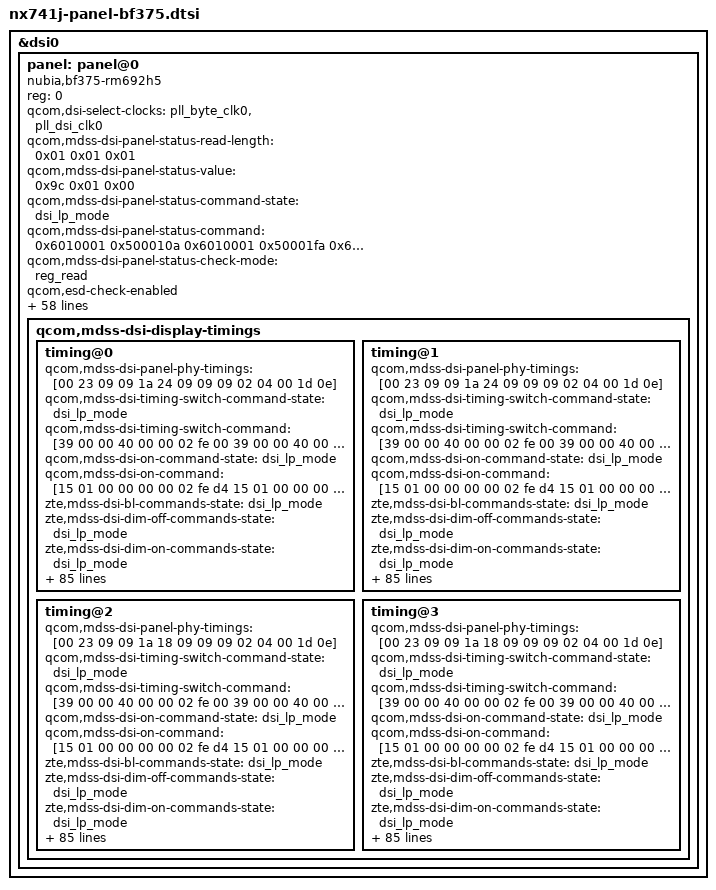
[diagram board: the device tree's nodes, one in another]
/*
 * Nubia Z80 Ultra (NX741J) display panel: BOE BF375 + Raydium RM692H5.
 *
 * Extracted from the live Android FDT (adb pull /sys/firmware/fdt) and reduced
 * to the properties the panel driver needs. Backlight is DCS command based
 * (qcom,mdss-dsi-bl-pmic-control-type = "bl_ctrl_dcs"), so it is driven with
 * the panel's own 0x51/0x53 commands rather than a PMIC PWM channel.
 *
 * Attached to the &dsi0 controller from nx741j-mdss.dtsi.  qcom,dsi-display-primary
 * in that file points qcom,dsi-default-panel at this node through the "panel"
 * label, and qcom,panel-supply-entries uses the dsi_panel_pwr_supply node.
 */

&dsi0 {
	panel: panel@0 {
		compatible = "nubia,bf375-rm692h5";
		reg = <0>;
				qcom,dsi-select-clocks = "pll_byte_clk0", "pll_dsi_clk0";
				qcom,mdss-dsi-panel-status-read-length = <0x01 0x01 0x01>;
				qcom,mdss-dsi-panel-status-value = <0x9c 0x01 0x00>;
				qcom,mdss-dsi-panel-status-command-state = "dsi_lp_mode";
				qcom,mdss-dsi-panel-status-command = <0x6010001 0x500010a 0x6010001 0x50001fa 0x6010001 0x500010b>;
				qcom,mdss-dsi-panel-status-check-mode = "reg_read";
				qcom,esd-check-enabled;
				qcom,ulps-enabled;
				qcom,platform-reset-gpio = <&tlmm 0x62 0x00>;
				qcom,mdss-dsi-bl-inverted-dbv;
				qcom,mdss-brightness-max-level = <0x1ffe>;
				qcom,mdss-dsi-bl-pmic-control-type = "bl_ctrl_dcs";
				qcom,panel-supply-entries = <&dsi_panel_pwr_supply>;
				zte,bl-normalmax-level = <0x1b76>;
				zte,te-high-width = <0x2134>;
				zte,bl_limit_enabled;
				zte,color_space_enabled;
				zte,acl_enabled;
				zte,aod_enabled;
				zte,fps_enabled;
				zte,hbm_enabled;
				qcom,mdss-disable-cesta-hw-sleep;
				qcom,bl-dsc-cmd-state = "dsi_lp_mode";
				qcom,bl-dcs-cmd-state = "dsi_lp_mode";
				qcom,mdss-pan-physical-height-dimension = <0x9e>;
				qcom,mdss-pan-physical-width-dimension = <0x48>;
				qcom,mdss-dsi-panel-blackness-level = <0x14>;
				qcom,mdss-dsi-panel-peak-brightness = <0x65edc0>;
				qcom,mdss-dsi-panel-hdr-color-primaries = <0x38a4 0x3c8c 0x84df 0x3e6c 0x32e6 0x876e 0x1b26 0xa05>;
				qcom,mdss-dsi-panel-hdr-enabled;
				qcom,mdss-dsi-bl-max-level = <0x1ffe>;
				qcom,mdss-dsi-bl-min-level = <0x02>;
				qcom,mdss-dsi-te-using-te-pin;
				qcom,mdss-dsi-te-check-enable;
				qcom,mdss-dsi-te-dcs-command = <0x01>;
				qcom,mdss-dsi-te-pin-select = <0x01>;
				qcom,mdss-dsi-reset-sequence = <0x01 0x0a 0x00 0x0a 0x01 0x28>;
				qcom,mdss-dsi-mdp-trigger = "none";
				qcom,mdss-dsi-dma-trigger = "trigger_sw";
				qcom,mdss-dsi-tx-eot-append;
				qcom,mdss-dsi-lp11-init;
				qcom,mdss-dsi-lane-3-state;
				qcom,mdss-dsi-lane-2-state;
				qcom,mdss-dsi-lane-1-state;
				qcom,mdss-dsi-lane-0-state;
				qcom,mdss-dsi-bllp-power-mode;
				qcom,mdss-dsi-bllp-eof-power-mode;
				qcom,mdss-dsi-lane-map = "lane_map_0123";
				qcom,mdss-dsi-traffic-mode = "burst_mode";
				qcom,dsi-phy-num = <0x00>;
				qcom,dsi-ctrl-num = <0x00>;
				qcom,mdss-dsi-border-color = <0x00>;
				qcom,mdss-dsi-underflow-color = <0xff>;
				qcom,mdss-dsi-color-order = "rgb_swap_rgb";
				qcom,mdss-dsi-bpp = <0x18>;
				qcom,mdss-dsi-stream = <0x00>;
				qcom,mdss-dsi-virtual-channel-id = <0x00>;
				qcom,mdss-dsi-panel-physical-type = "oled";
				qcom,mdss-dsi-panel-type = "dsi_cmd_mode";
				qcom,mdss-dsi-panel-name = "BF375_RM692H5_6P8_DEV0_DSC_CMD";

				qcom,mdss-dsi-display-timings {

					timing@0 {
						qcom,mdss-dsi-panel-phy-timings = [00 23 09 09 1a 24 09 09 09 02 04 00 1d 0e];
						qcom,mdss-dsi-timing-switch-command-state = "dsi_lp_mode";
						qcom,mdss-dsi-timing-switch-command = [39 00 00 40 00 00 02 fe 00 39 00 00 40 00 00 02 2f 07 39 00 00 40 00 00 02 fe 5a 39 00 00 40 00 00 02 47 f0 39 00 00 40 00 00 02 48 df 39 00 00 40 00 00 02 49 20 39 00 00 40 00 00 02 4a ee 39 00 00 40 00 00 02 4b ee 39 00 00 40 00 00 02 4c ee 39 00 00 40 00 00 02 4f 10 39 00 00 40 00 00 02 50 16 39 00 00 40 00 00 02 51 00 39 00 00 40 00 00 02 53 08 39 00 00 40 00 00 02 58 00 39 00 00 40 00 00 02 59 00 39 00 00 40 00 00 02 60 00 39 00 00 40 00 00 02 61 00 39 00 00 40 00 00 02 68 f6 39 00 00 40 00 00 02 69 00 39 00 00 40 00 00 02 70 00 39 00 00 40 00 00 02 79 00 39 00 00 40 00 00 02 7a ff 39 00 00 40 00 00 02 7f 01 39 00 00 40 00 00 02 80 00 39 00 00 40 00 00 02 88 ff 39 00 00 40 00 00 02 89 ff 39 00 00 40 00 00 02 8a ff 39 00 00 40 00 00 02 8c 00 39 00 00 40 00 00 02 90 20 39 00 00 40 00 00 02 91 30 39 00 00 40 00 00 02 92 00 39 00 00 40 00 00 02 93 10 39 00 00 40 00 00 02 94 09 39 00 00 40 00 00 02 95 10 39 00 00 40 00 00 02 98 0c 39 00 00 40 00 00 02 99 01 39 00 00 40 00 00 02 9a 02 39 00 00 40 00 00 02 a0 02 39 00 00 40 00 00 02 a2 06 39 00 00 40 00 00 02 a3 04 39 00 00 40 00 00 02 aa 00 39 00 00 40 00 00 02 ab 02 39 00 00 40 00 00 02 b2 06 39 00 00 40 00 00 02 b3 02 39 00 00 40 00 00 02 ba 01 39 00 00 40 00 00 02 bb 03 39 00 00 40 00 00 02 bc 02 39 00 00 40 00 00 02 bd 03 39 00 00 40 00 00 02 c2 03 39 00 00 40 00 00 02 c3 03 39 00 00 40 00 00 02 c4 02 39 00 00 40 00 00 02 c9 02 39 00 00 40 00 00 02 ca 01 39 00 00 40 00 00 02 cb 01 39 00 00 40 00 00 02 da 40 39 00 00 40 00 00 02 db 30 39 00 00 40 00 00 02 dc 2a 39 00 00 40 00 00 02 dd 06 39 00 00 40 00 00 02 de 10 39 00 00 40 00 00 02 df 06 39 00 00 40 00 00 02 e2 1f 39 00 00 40 00 00 02 e3 20 39 00 00 40 00 00 02 e4 0d 39 00 00 40 00 00 02 ea 12 39 00 00 40 00 00 02 eb 10 39 00 00 40 00 00 02 ec 10 39 00 00 40 00 00 02 f3 04 39 00 00 40 00 00 02 f4 06 39 00 00 40 00 00 02 fe 5b 39 00 00 40 00 00 02 01 10 39 00 00 40 00 00 02 02 06 39 00 00 40 00 00 02 03 02 39 00 00 40 00 00 02 09 03 39 00 00 40 00 00 02 0a 02 39 00 00 40 00 00 02 11 02 39 00 00 40 00 00 02 12 02 39 00 00 40 00 00 02 18 02 39 00 00 40 00 00 02 19 02 39 00 00 40 00 00 02 1b ff 39 00 00 40 00 00 02 21 02 39 00 00 40 00 00 02 22 01 39 00 00 40 00 00 02 23 01 39 00 00 40 00 00 02 24 01 39 00 00 40 00 00 02 25 02 39 00 00 40 00 00 02 29 7f 39 00 00 40 00 00 02 2b fd 39 00 00 40 00 00 02 2d 1f 39 00 00 40 00 00 02 2f 1b 39 00 00 40 00 00 02 30 36 39 00 00 40 00 00 02 33 f9 39 00 00 40 00 00 02 34 00 39 00 00 40 00 00 02 35 fc 39 00 00 40 00 00 02 3b fd 39 00 00 40 00 00 02 3d ff 39 00 00 40 00 00 02 45 fb 39 00 00 40 00 00 02 46 00 39 00 00 40 00 00 02 55 00 39 00 00 40 00 00 02 56 fd 39 00 00 40 00 00 02 5e ff 39 00 00 40 00 00 02 5f 01 39 00 00 40 00 00 02 60 02 39 00 00 40 00 00 02 65 fe 39 00 00 40 00 00 02 66 ff 39 00 00 40 00 00 02 67 01 39 00 00 40 00 00 02 6e 01 39 00 00 40 00 00 02 6f 01 39 00 00 40 00 00 02 70 01 39 00 00 40 00 00 02 71 00 39 00 00 00 00 00 02 fe 00];
						qcom,mdss-dsi-on-command-state = "dsi_lp_mode";
						qcom,mdss-dsi-on-command = [15 01 00 00 00 00 02 fe d4 15 01 00 00 00 00 02 40 03 15 01 00 00 00 00 02 fe fd 15 01 00 00 00 00 02 80 06 15 01 00 00 00 00 02 83 00 15 01 00 00 00 00 02 ee 00 15 01 00 00 00 00 02 ef 00 15 01 00 00 00 00 02 fe d0 15 01 00 00 00 00 02 7e 80 15 01 00 00 00 00 02 fe b6 15 01 00 00 00 00 02 01 74 15 01 00 00 00 00 02 fe a1 15 01 00 00 00 00 02 74 72 15 01 00 00 00 00 02 c3 c3 15 01 00 00 00 00 02 c4 ff 15 01 00 00 00 00 02 c5 7f 15 01 00 00 00 00 02 fe 00 15 01 00 00 00 00 02 fa 01 15 01 00 00 00 00 02 fe d2 15 01 00 00 00 00 02 97 08 15 01 00 00 00 00 02 36 11 15 01 00 00 00 00 02 39 ab 15 01 00 00 00 00 02 3a 30 15 01 00 00 00 00 02 3b 80 15 01 00 00 00 00 02 3d 0a 15 01 00 00 00 00 02 3f 80 15 01 00 00 00 00 02 40 04 15 01 00 00 00 00 02 41 c0 15 01 00 00 00 00 02 42 00 15 01 00 00 00 00 02 43 10 15 01 00 00 00 00 02 44 02 15 01 00 00 00 00 02 45 60 15 01 00 00 00 00 02 46 02 15 01 00 00 00 00 02 47 60 15 01 00 00 00 00 02 48 02 15 01 00 00 00 00 02 49 00 15 01 00 00 00 00 02 4a 02 15 01 00 00 00 00 02 4b 31 15 01 00 00 00 00 02 4d 20 15 01 00 00 00 00 02 4e 01 15 01 00 00 00 00 02 4f 68 15 01 00 00 00 00 02 50 00 15 01 00 00 00 00 02 51 08 15 01 00 00 00 00 02 53 0c 15 01 00 00 00 00 02 54 06 15 01 00 00 00 00 02 55 67 15 01 00 00 00 00 02 56 05 15 01 00 00 00 00 02 58 ad 15 01 00 00 00 00 02 59 18 15 01 00 00 00 00 02 5a 00 15 01 00 00 00 00 02 5b 11 15 01 00 00 00 00 02 5c 00 15 01 00 00 00 00 02 5d 07 15 01 00 00 00 00 02 5e 10 15 01 00 00 00 00 02 5f 20 15 01 00 00 00 00 02 60 00 15 01 00 00 00 00 02 61 06 15 01 00 00 00 00 02 62 0f 15 01 00 00 00 00 02 63 0f 15 01 00 00 00 00 02 64 33 15 01 00 00 00 00 02 65 0e 15 01 00 00 00 00 02 66 1c 15 01 00 00 00 00 02 67 2a 15 01 00 00 00 00 02 68 38 15 01 00 00 00 00 02 69 46 15 01 00 00 00 00 02 6a 54 15 01 00 00 00 00 02 6b 62 15 01 00 00 00 00 02 6c 69 15 01 00 00 00 00 02 6d 70 15 01 00 00 00 00 02 6e 77 15 01 00 00 00 00 02 6f 79 15 01 00 00 00 00 02 70 7b 15 01 00 00 00 00 02 71 7d 15 01 00 00 00 00 02 72 7e 15 01 00 00 00 00 02 73 02 15 01 00 00 00 00 02 74 02 15 01 00 00 00 00 02 75 22 15 01 00 00 00 00 02 76 00 15 01 00 00 00 00 02 77 2a 15 01 00 00 00 00 02 78 40 15 01 00 00 00 00 02 79 2a 15 01 00 00 00 00 02 7a be 15 01 00 00 00 00 02 7b 3a 15 01 00 00 00 00 02 7c fc 15 01 00 00 00 00 02 7d 3a 15 01 00 00 00 00 02 7e fa 15 01 00 00 00 00 02 7f 3a 15 01 00 00 00 00 02 80 f8 15 01 00 00 00 00 02 81 3b 15 01 00 00 00 00 02 82 38 15 01 00 00 00 00 02 83 3b 15 01 00 00 00 00 02 84 78 15 01 00 00 00 00 02 85 3b 15 01 00 00 00 00 02 86 b6 15 01 00 00 00 00 02 87 4b 15 01 00 00 00 00 02 88 f6 15 01 00 00 00 00 02 89 4c 15 01 00 00 00 00 02 8a 34 15 01 00 00 00 00 02 8b 4c 15 01 00 00 00 00 02 8c 74 15 01 00 00 00 00 02 8d 5c 15 01 00 00 00 00 02 8e 74 15 01 00 00 00 00 02 8f 8c 15 01 00 00 00 00 02 90 f4 15 01 00 00 00 00 02 91 00 15 01 00 00 00 00 02 92 00 15 01 00 00 00 00 02 93 00 15 01 00 00 00 00 02 94 00 15 01 00 00 00 00 02 95 00 15 01 00 00 00 00 02 96 00 15 01 00 00 00 00 02 fe 34 15 01 00 00 00 00 02 82 c0 15 01 00 00 00 00 02 83 04 15 01 00 00 00 00 02 00 08 15 01 00 00 00 00 02 1c 00 15 01 00 00 00 00 02 1d 10 15 01 00 00 00 00 02 49 05 15 01 00 00 00 00 02 1e 00 15 01 00 00 00 00 02 1f 00 15 01 00 00 00 00 02 20 00 15 01 00 00 00 00 02 21 70 15 01 00 00 00 00 02 22 00 15 01 00 00 00 00 02 23 f8 15 01 00 00 00 00 02 24 77 15 01 00 00 00 00 02 25 f8 15 01 00 00 00 00 02 26 f8 15 01 00 00 00 00 02 2f 00 15 01 00 00 00 00 02 30 00 15 01 00 00 00 00 02 31 00 15 01 00 00 00 00 02 32 00 15 01 00 00 00 00 02 33 00 15 01 00 00 00 00 02 34 00 15 01 00 00 00 00 02 35 00 15 01 00 00 00 00 02 36 c4 15 01 00 00 00 00 02 37 00 15 01 00 00 00 00 02 38 87 15 01 00 00 00 00 02 39 00 15 01 00 00 00 00 02 3a 4b 15 01 00 00 00 00 02 3b 00 15 01 00 00 00 00 02 3d 00 15 01 00 00 00 00 02 3f 00 15 01 00 00 00 00 02 40 00 15 01 00 00 00 00 02 41 00 15 01 00 00 00 00 02 42 00 15 01 00 00 00 00 02 54 03 15 01 00 00 00 00 02 55 77 15 01 00 00 00 00 02 56 f8 15 01 00 00 00 00 02 58 f8 15 01 00 00 00 00 02 59 77 15 01 00 00 00 00 02 5a f8 15 01 00 00 00 00 02 5b f8 15 01 00 00 00 00 02 5c 77 15 01 00 00 00 00 02 5d f8 15 01 00 00 00 00 02 5e f8 15 01 00 00 00 00 02 5f 77 15 01 00 00 00 00 02 60 f8 15 01 00 00 00 00 02 61 f8 15 01 00 00 00 00 02 62 77 15 01 00 00 00 00 02 63 f8 15 01 00 00 00 00 02 64 f8 15 01 00 00 00 00 02 65 77 15 01 00 00 00 00 02 66 f8 15 01 00 00 00 00 02 67 f8 15 01 00 00 00 00 02 77 07 15 01 00 00 00 00 02 78 f8 15 01 00 00 00 00 02 fe 00 15 01 00 00 00 00 02 2f 07 15 01 00 00 00 00 02 fe 5a 15 01 00 00 00 00 02 47 f0 15 01 00 00 00 00 02 48 df 15 01 00 00 00 00 02 49 20 15 01 00 00 00 00 02 4a ee 15 01 00 00 00 00 02 4b ee 15 01 00 00 00 00 02 4c ee 15 01 00 00 00 00 02 4f 10 15 01 00 00 00 00 02 50 16 15 01 00 00 00 00 02 51 00 15 01 00 00 00 00 02 53 08 15 01 00 00 00 00 02 58 00 15 01 00 00 00 00 02 59 00 15 01 00 00 00 00 02 60 00 15 01 00 00 00 00 02 61 00 15 01 00 00 00 00 02 68 f6 15 01 00 00 00 00 02 69 00 15 01 00 00 00 00 02 70 00 15 01 00 00 00 00 02 79 00 15 01 00 00 00 00 02 7a ff 15 01 00 00 00 00 02 7f 01 15 01 00 00 00 00 02 80 00 15 01 00 00 00 00 02 88 ff 15 01 00 00 00 00 02 89 ff 15 01 00 00 00 00 02 8a ff 15 01 00 00 00 00 02 8c 00 15 01 00 00 00 00 02 90 20 15 01 00 00 00 00 02 91 30 15 01 00 00 00 00 02 92 00 15 01 00 00 00 00 02 93 10 15 01 00 00 00 00 02 94 09 15 01 00 00 00 00 02 95 10 15 01 00 00 00 00 02 98 0c 15 01 00 00 00 00 02 99 01 15 01 00 00 00 00 02 9a 02 15 01 00 00 00 00 02 a0 02 15 01 00 00 00 00 02 a2 06 15 01 00 00 00 00 02 a3 04 15 01 00 00 00 00 02 aa 00 15 01 00 00 00 00 02 ab 02 15 01 00 00 00 00 02 b2 06 15 01 00 00 00 00 02 b3 02 15 01 00 00 00 00 02 ba 01 15 01 00 00 00 00 02 bb 03 15 01 00 00 00 00 02 bc 02 15 01 00 00 00 00 02 bd 03 15 01 00 00 00 00 02 c2 03 15 01 00 00 00 00 02 c3 03 15 01 00 00 00 00 02 c4 02 15 01 00 00 00 00 02 c9 02 15 01 00 00 00 00 02 ca 01 15 01 00 00 00 00 02 cb 01 15 01 00 00 00 00 02 da 40 15 01 00 00 00 00 02 db 30 15 01 00 00 00 00 02 dc 2a 15 01 00 00 00 00 02 dd 06 15 01 00 00 00 00 02 de 10 15 01 00 00 00 00 02 df 06 15 01 00 00 00 00 02 e2 1f 15 01 00 00 00 00 02 e3 20 15 01 00 00 00 00 02 e4 0d 15 01 00 00 00 00 02 ea 12 15 01 00 00 00 00 02 eb 10 15 01 00 00 00 00 02 ec 10 15 01 00 00 00 00 02 f3 04 15 01 00 00 00 00 02 f4 06 15 01 00 00 00 00 02 fe 5b 15 01 00 00 00 00 02 01 10 15 01 00 00 00 00 02 02 06 15 01 00 00 00 00 02 03 02 15 01 00 00 00 00 02 09 03 15 01 00 00 00 00 02 0a 02 15 01 00 00 00 00 02 11 02 15 01 00 00 00 00 02 12 02 15 01 00 00 00 00 02 18 02 15 01 00 00 00 00 02 19 02 15 01 00 00 00 00 02 1b ff 15 01 00 00 00 00 02 21 02 15 01 00 00 00 00 02 22 01 15 01 00 00 00 00 02 23 01 15 01 00 00 00 00 02 24 01 15 01 00 00 00 00 02 25 02 15 01 00 00 00 00 02 29 7f 15 01 00 00 00 00 02 2b fd 15 01 00 00 00 00 02 2d 1f 15 01 00 00 00 00 02 2f 1b 15 01 00 00 00 00 02 30 36 15 01 00 00 00 00 02 33 f9 15 01 00 00 00 00 02 34 00 15 01 00 00 00 00 02 35 fc 15 01 00 00 00 00 02 3b fd 15 01 00 00 00 00 02 3d ff 15 01 00 00 00 00 02 45 fb 15 01 00 00 00 00 02 46 00 15 01 00 00 00 00 02 55 00 15 01 00 00 00 00 02 56 fd 15 01 00 00 00 00 02 5e ff 15 01 00 00 00 00 02 5f 01 15 01 00 00 00 00 02 60 02 15 01 00 00 00 00 02 65 fe 15 01 00 00 00 00 02 66 ff 15 01 00 00 00 00 02 67 01 15 01 00 00 00 00 02 6e 01 15 01 00 00 00 00 02 6f 01 15 01 00 00 00 00 02 70 01 15 01 00 00 00 00 02 71 00 15 01 00 00 00 00 02 fe 9b 15 01 00 00 00 00 02 0b 4e 15 01 00 00 00 00 02 fe 00 15 01 00 00 00 00 02 c2 08 15 01 00 00 00 00 02 35 00 15 01 00 00 00 00 02 53 20 39 01 00 00 00 00 03 51 00 00 05 01 00 00 64 00 01 11 05 01 00 00 14 00 01 29];
						zte,mdss-dsi-bl-commands-state = "dsi_lp_mode";
						zte,mdss-dsi-dim-off-commands-state = "dsi_lp_mode";
						zte,mdss-dsi-dim-on-commands-state = "dsi_lp_mode";
						zte,mdss-dsi-hbm-off-aod-on-commands-state = "dsi_lp_mode";
						zte,mdss-dsi-reg-read-commands-state = "dsi_lp_mode";
						zte,mdss-dsi-aod-off-hbm-on-commands-state = "dsi_lp_mode";
						zte,mdss-dsi-restore-bl-commands-state = "dsi_lp_mode";
						zte,mdss-dsi-aod-high-commands-state = "dsi_lp_mode";
						zte,mdss-dsi-aod-mid-commands-state = "dsi_lp_mode";
						zte,mdss-dsi-aod-low-commands-state = "dsi_lp_mode";
						zte,mdss-dsi-hbm-off-commands-state = "dsi_lp_mode";
						zte,mdss-dsi-hbm-on-commands-state = "dsi_lp_mode";
						zte,mdss-dsi-bl-commands = [15 01 00 00 00 00 02 fe 00 39 01 00 00 00 00 03 51 03 ff];
						zte,mdss-dsi-dim-off-commands = [15 01 00 00 00 00 02 fe 00 15 01 00 00 00 00 02 53 20];
						zte,mdss-dsi-dim-on-commands = [15 01 00 00 00 00 02 fe 00 15 01 00 00 00 00 02 53 28];
						zte,mdss-dsi-hbm-off-aod-on-commands = [15 01 00 00 00 00 02 fe 00 39 01 00 00 00 00 03 51 00 00 05 01 00 00 00 00 01 39 39 01 00 00 00 00 03 51 01 20];
						zte,mdss-dsi-reg-read-commands = <0x6010000 0x1a0>;
						zte,mdss-dsi-aod-off-hbm-on-commands = [15 01 00 00 00 00 02 fe 00 05 01 00 00 00 00 01 38 39 01 00 00 00 00 03 51 1f fe];
						zte,mdss-dsi-acl-high-commands = [15 01 00 00 00 00 02 fe 00 15 01 00 00 00 00 02 55 11];
						zte,mdss-dsi-acl-mid-commands = [15 01 00 00 00 00 02 fe 00 15 01 00 00 00 00 02 55 12];
						zte,mdss-dsi-acl-low-commands = [15 01 00 00 00 00 02 fe 00 15 01 00 00 00 00 02 55 13];
						zte,mdss-dsi-acl-off-commands = [15 01 00 00 00 00 02 fe 00 15 01 00 00 00 00 02 55 10];
						zte,mdss-dsi-restore-bl-commands = [15 01 00 00 00 00 02 fe 00 39 01 00 00 00 00 03 51 03 ff];
						zte,mdss-dsi-aod-high-commands = [15 01 00 00 00 00 02 fe 00 39 01 00 00 00 00 03 51 1f fc];
						zte,mdss-dsi-aod-mid-commands = [15 01 00 00 00 00 02 fe 00 39 01 00 00 00 00 03 51 0a ae];
						zte,mdss-dsi-aod-low-commands = [15 01 00 00 00 00 02 fe 00 39 01 00 00 00 00 03 51 00 08];
						zte,mdss-dsi-hbm-off-commands = <0x15010000 0x2fe 0x390100 0x02 0x53203901 0x00 0x3510322>;
						zte,mdss-dsi-hbm-on-commands = <0x15010000 0x2fe 0x390100 0x02 0x53203901 0x00 0x3511ffe>;
						qcom,mdss-dsi-nolp-command-state = "dsi_lp_mode";
						qcom,mdss-dsi-nolp-command = [15 01 00 00 00 00 02 fe 00 39 01 00 00 00 00 03 51 00 00 05 01 00 00 00 00 01 38];
						qcom,mdss-dsi-lp1-command-state = "dsi_lp_mode";
						qcom,mdss-dsi-lp1-command = [15 01 00 00 00 00 02 fe 00 05 01 00 00 14 00 01 39];
						qcom,mdss-dsi-off-command-state = "dsi_lp_mode";
						qcom,mdss-dsi-off-command = [15 01 00 00 14 00 02 fe 00 05 01 00 00 10 00 01 28 05 01 00 00 78 00 01 10];
						qcom,default-topology-index = <0x00>;
						qcom,display-topology = <0x02 0x02 0x01>;
						qcom,mdss-dsc-block-prediction-enable;
						qcom,mdss-dsc-bit-per-pixel = <0x08>;
						qcom,mdss-dsc-bit-per-component = <0x0a>;
						qcom,mdss-dsc-slice-per-pkt = <0x02>;
						qcom,mdss-dsc-slice-width = <0x260>;
						qcom,mdss-dsc-slice-height = <0x10>;
						qcom,compression-mode = "dsc";
						qcom,mdss-mdp-transfer-time-us = <0x185b>;
						qcom,mdss-dsi-panel-framerate = <0x3c>;
						qcom,mdss-dsi-v-bottom-border = <0x00>;
						qcom,mdss-dsi-v-top-border = <0x00>;
						qcom,mdss-dsi-h-right-border = <0x00>;
						qcom,mdss-dsi-h-left-border = <0x00>;
						qcom,mdss-dsi-h-sync-pulse = <0x00>;
						qcom,mdss-dsi-v-pulse-width = <0x08>;
						qcom,mdss-dsi-v-front-porch = <0x38>;
						qcom,mdss-dsi-v-back-porch = <0x08>;
						qcom,mdss-dsi-h-sync-skew = <0x00>;
						qcom,mdss-dsi-h-pulse-width = <0x08>;
						qcom,mdss-dsi-h-back-porch = <0x110>;
						qcom,mdss-dsi-h-front-porch = <0xf8>;
						qcom,mdss-dsi-panel-height = <0xa80>;
						qcom,mdss-dsi-panel-width = <0x4c0>;
						cell-index = <0x00>;
					};

					timing@1 {
						qcom,mdss-dsi-panel-phy-timings = [00 23 09 09 1a 24 09 09 09 02 04 00 1d 0e];
						qcom,mdss-dsi-timing-switch-command-state = "dsi_lp_mode";
						qcom,mdss-dsi-timing-switch-command = [39 00 00 40 00 00 02 fe 00 39 00 00 40 00 00 02 2f 06 39 00 00 40 00 00 02 fe 5a 39 00 00 40 00 00 02 47 ff 39 00 00 40 00 00 02 48 df 39 00 00 40 00 00 02 49 10 39 00 00 40 00 00 02 4a fc 39 00 00 40 00 00 02 4b ff 39 00 00 40 00 00 02 4f 10 39 00 00 40 00 00 02 50 ff 39 00 00 40 00 00 02 51 fe 39 00 00 40 00 00 02 53 08 39 00 00 40 00 00 02 58 05 39 00 00 40 00 00 02 60 fd 39 00 00 40 00 00 02 61 00 39 00 00 40 00 00 02 68 fd 39 00 00 40 00 00 02 69 00 39 00 00 40 00 00 02 70 01 39 00 00 40 00 00 02 79 00 39 00 00 40 00 00 02 7a ff 39 00 00 40 00 00 02 7f 01 39 00 00 40 00 00 02 80 fe 39 00 00 40 00 00 02 88 ff 39 00 00 40 00 00 02 89 ff 39 00 00 40 00 00 02 8a ff 39 00 00 40 00 00 02 8c 00 39 00 00 40 00 00 02 90 00 39 00 00 40 00 00 02 91 40 39 00 00 40 00 00 02 92 0b 39 00 00 40 00 00 02 93 14 39 00 00 40 00 00 02 94 0f 39 00 00 40 00 00 02 95 03 39 00 00 40 00 00 02 98 0c 39 00 00 40 00 00 02 99 08 39 00 00 40 00 00 02 9a 08 39 00 00 40 00 00 02 a0 0b 39 00 00 40 00 00 02 a2 06 39 00 00 40 00 00 02 a3 06 39 00 00 40 00 00 02 aa 07 39 00 00 40 00 00 02 ab 02 39 00 00 40 00 00 02 b2 07 39 00 00 40 00 00 02 b3 05 39 00 00 40 00 00 02 ba 04 39 00 00 40 00 00 02 bb 03 39 00 00 40 00 00 02 bc 02 39 00 00 40 00 00 02 bd 03 39 00 00 40 00 00 02 c2 03 39 00 00 40 00 00 02 c3 03 39 00 00 40 00 00 02 c4 02 39 00 00 40 00 00 02 c9 02 39 00 00 40 00 00 02 ca 02 39 00 00 40 00 00 02 cb 01 39 00 00 40 00 00 02 da 70 39 00 00 40 00 00 02 db 30 39 00 00 40 00 00 02 dc 30 39 00 00 40 00 00 02 dd 1c 39 00 00 40 00 00 02 de 02 39 00 00 40 00 00 02 df 1b 39 00 00 40 00 00 02 e2 1f 39 00 00 40 00 00 02 e3 20 39 00 00 40 00 00 02 e4 18 39 00 00 40 00 00 02 ea 18 39 00 00 40 00 00 02 eb 10 39 00 00 40 00 00 02 ec 14 39 00 00 40 00 00 02 f3 0c 39 00 00 40 00 00 02 f4 06 39 00 00 40 00 00 02 fe 5b 39 00 00 40 00 00 02 01 10 39 00 00 40 00 00 02 02 08 39 00 00 40 00 00 02 03 04 39 00 00 40 00 00 02 09 06 39 00 00 40 00 00 02 0a 05 39 00 00 40 00 00 02 11 02 39 00 00 40 00 00 02 12 02 39 00 00 40 00 00 02 18 02 39 00 00 40 00 00 02 19 07 39 00 00 40 00 00 02 1b ff 39 00 00 40 00 00 02 21 02 39 00 00 40 00 00 02 22 01 39 00 00 40 00 00 02 23 01 39 00 00 40 00 00 02 24 01 39 00 00 40 00 00 02 25 02 39 00 00 40 00 00 02 29 10 39 00 00 40 00 00 02 2b 20 39 00 00 40 00 00 02 2d 1c 39 00 00 40 00 00 02 2f 10 39 00 00 40 00 00 02 30 22 39 00 00 40 00 00 02 33 f9 39 00 00 40 00 00 02 34 ff 39 00 00 40 00 00 02 35 00 39 00 00 40 00 00 02 3b f9 39 00 00 40 00 00 02 3d 00 39 00 00 40 00 00 02 45 fe 39 00 00 40 00 00 02 46 00 39 00 00 40 00 00 02 55 ff 39 00 00 40 00 00 02 56 fd 39 00 00 40 00 00 02 5e ff 39 00 00 40 00 00 02 5f 01 39 00 00 40 00 00 02 60 02 39 00 00 40 00 00 02 65 fe 39 00 00 40 00 00 02 66 01 39 00 00 40 00 00 02 67 fc 39 00 00 40 00 00 02 6e 01 39 00 00 40 00 00 02 6f 01 39 00 00 40 00 00 02 70 01 39 00 00 40 00 00 02 71 00 39 00 00 00 00 00 02 fe 00];
						qcom,mdss-dsi-on-command-state = "dsi_lp_mode";
						qcom,mdss-dsi-on-command = [15 01 00 00 00 00 02 fe d4 15 01 00 00 00 00 02 40 03 15 01 00 00 00 00 02 fe fd 15 01 00 00 00 00 02 80 06 15 01 00 00 00 00 02 83 00 15 01 00 00 00 00 02 ee 00 15 01 00 00 00 00 02 ef 00 15 01 00 00 00 00 02 fe d0 15 01 00 00 00 00 02 7e 80 15 01 00 00 00 00 02 fe b6 15 01 00 00 00 00 02 01 74 15 01 00 00 00 00 02 fe a1 15 01 00 00 00 00 02 74 72 15 01 00 00 00 00 02 c3 c3 15 01 00 00 00 00 02 c4 ff 15 01 00 00 00 00 02 c5 7f 15 01 00 00 00 00 02 fe 00 15 01 00 00 00 00 02 fa 01 15 01 00 00 00 00 02 fe d2 15 01 00 00 00 00 02 97 08 15 01 00 00 00 00 02 36 11 15 01 00 00 00 00 02 39 ab 15 01 00 00 00 00 02 3a 30 15 01 00 00 00 00 02 3b 80 15 01 00 00 00 00 02 3d 0a 15 01 00 00 00 00 02 3f 80 15 01 00 00 00 00 02 40 04 15 01 00 00 00 00 02 41 c0 15 01 00 00 00 00 02 42 00 15 01 00 00 00 00 02 43 10 15 01 00 00 00 00 02 44 02 15 01 00 00 00 00 02 45 60 15 01 00 00 00 00 02 46 02 15 01 00 00 00 00 02 47 60 15 01 00 00 00 00 02 48 02 15 01 00 00 00 00 02 49 00 15 01 00 00 00 00 02 4a 02 15 01 00 00 00 00 02 4b 31 15 01 00 00 00 00 02 4d 20 15 01 00 00 00 00 02 4e 01 15 01 00 00 00 00 02 4f 68 15 01 00 00 00 00 02 50 00 15 01 00 00 00 00 02 51 08 15 01 00 00 00 00 02 53 0c 15 01 00 00 00 00 02 54 06 15 01 00 00 00 00 02 55 67 15 01 00 00 00 00 02 56 05 15 01 00 00 00 00 02 58 ad 15 01 00 00 00 00 02 59 18 15 01 00 00 00 00 02 5a 00 15 01 00 00 00 00 02 5b 11 15 01 00 00 00 00 02 5c 00 15 01 00 00 00 00 02 5d 07 15 01 00 00 00 00 02 5e 10 15 01 00 00 00 00 02 5f 20 15 01 00 00 00 00 02 60 00 15 01 00 00 00 00 02 61 06 15 01 00 00 00 00 02 62 0f 15 01 00 00 00 00 02 63 0f 15 01 00 00 00 00 02 64 33 15 01 00 00 00 00 02 65 0e 15 01 00 00 00 00 02 66 1c 15 01 00 00 00 00 02 67 2a 15 01 00 00 00 00 02 68 38 15 01 00 00 00 00 02 69 46 15 01 00 00 00 00 02 6a 54 15 01 00 00 00 00 02 6b 62 15 01 00 00 00 00 02 6c 69 15 01 00 00 00 00 02 6d 70 15 01 00 00 00 00 02 6e 77 15 01 00 00 00 00 02 6f 79 15 01 00 00 00 00 02 70 7b 15 01 00 00 00 00 02 71 7d 15 01 00 00 00 00 02 72 7e 15 01 00 00 00 00 02 73 02 15 01 00 00 00 00 02 74 02 15 01 00 00 00 00 02 75 22 15 01 00 00 00 00 02 76 00 15 01 00 00 00 00 02 77 2a 15 01 00 00 00 00 02 78 40 15 01 00 00 00 00 02 79 2a 15 01 00 00 00 00 02 7a be 15 01 00 00 00 00 02 7b 3a 15 01 00 00 00 00 02 7c fc 15 01 00 00 00 00 02 7d 3a 15 01 00 00 00 00 02 7e fa 15 01 00 00 00 00 02 7f 3a 15 01 00 00 00 00 02 80 f8 15 01 00 00 00 00 02 81 3b 15 01 00 00 00 00 02 82 38 15 01 00 00 00 00 02 83 3b 15 01 00 00 00 00 02 84 78 15 01 00 00 00 00 02 85 3b 15 01 00 00 00 00 02 86 b6 15 01 00 00 00 00 02 87 4b 15 01 00 00 00 00 02 88 f6 15 01 00 00 00 00 02 89 4c 15 01 00 00 00 00 02 8a 34 15 01 00 00 00 00 02 8b 4c 15 01 00 00 00 00 02 8c 74 15 01 00 00 00 00 02 8d 5c 15 01 00 00 00 00 02 8e 74 15 01 00 00 00 00 02 8f 8c 15 01 00 00 00 00 02 90 f4 15 01 00 00 00 00 02 91 00 15 01 00 00 00 00 02 92 00 15 01 00 00 00 00 02 93 00 15 01 00 00 00 00 02 94 00 15 01 00 00 00 00 02 95 00 15 01 00 00 00 00 02 96 00 15 01 00 00 00 00 02 fe 34 15 01 00 00 00 00 02 82 c0 15 01 00 00 00 00 02 83 04 15 01 00 00 00 00 02 00 08 15 01 00 00 00 00 02 1c 00 15 01 00 00 00 00 02 1d 10 15 01 00 00 00 00 02 49 05 15 01 00 00 00 00 02 1e 00 15 01 00 00 00 00 02 1f 00 15 01 00 00 00 00 02 20 00 15 01 00 00 00 00 02 21 70 15 01 00 00 00 00 02 22 00 15 01 00 00 00 00 02 23 f8 15 01 00 00 00 00 02 24 77 15 01 00 00 00 00 02 25 f8 15 01 00 00 00 00 02 26 f8 15 01 00 00 00 00 02 2f 00 15 01 00 00 00 00 02 30 00 15 01 00 00 00 00 02 31 00 15 01 00 00 00 00 02 32 00 15 01 00 00 00 00 02 33 00 15 01 00 00 00 00 02 34 00 15 01 00 00 00 00 02 35 00 15 01 00 00 00 00 02 36 c4 15 01 00 00 00 00 02 37 00 15 01 00 00 00 00 02 38 87 15 01 00 00 00 00 02 39 00 15 01 00 00 00 00 02 3a 4b 15 01 00 00 00 00 02 3b 00 15 01 00 00 00 00 02 3d 00 15 01 00 00 00 00 02 3f 00 15 01 00 00 00 00 02 40 00 15 01 00 00 00 00 02 41 00 15 01 00 00 00 00 02 42 00 15 01 00 00 00 00 02 54 03 15 01 00 00 00 00 02 55 77 15 01 00 00 00 00 02 56 f8 15 01 00 00 00 00 02 58 f8 15 01 00 00 00 00 02 59 77 15 01 00 00 00 00 02 5a f8 15 01 00 00 00 00 02 5b f8 15 01 00 00 00 00 02 5c 77 15 01 00 00 00 00 02 5d f8 15 01 00 00 00 00 02 5e f8 15 01 00 00 00 00 02 5f 77 15 01 00 00 00 00 02 60 f8 15 01 00 00 00 00 02 61 f8 15 01 00 00 00 00 02 62 77 15 01 00 00 00 00 02 63 f8 15 01 00 00 00 00 02 64 f8 15 01 00 00 00 00 02 65 77 15 01 00 00 00 00 02 66 f8 15 01 00 00 00 00 02 67 f8 15 01 00 00 00 00 02 77 07 15 01 00 00 00 00 02 78 f8 15 01 00 00 00 00 02 fe 00 15 01 00 00 00 00 02 2f 06 15 01 00 00 00 00 02 fe 5a 15 01 00 00 00 00 02 47 ff 15 01 00 00 00 00 02 48 df 15 01 00 00 00 00 02 49 10 15 01 00 00 00 00 02 4a fc 15 01 00 00 00 00 02 4b ff 15 01 00 00 00 00 02 4f 10 15 01 00 00 00 00 02 50 ff 15 01 00 00 00 00 02 51 fe 15 01 00 00 00 00 02 53 08 15 01 00 00 00 00 02 58 05 15 01 00 00 00 00 02 60 fd 15 01 00 00 00 00 02 61 00 15 01 00 00 00 00 02 68 fd 15 01 00 00 00 00 02 69 00 15 01 00 00 00 00 02 70 01 15 01 00 00 00 00 02 79 00 15 01 00 00 00 00 02 7a ff 15 01 00 00 00 00 02 7f 01 15 01 00 00 00 00 02 80 fe 15 01 00 00 00 00 02 88 ff 15 01 00 00 00 00 02 89 ff 15 01 00 00 00 00 02 8a ff 15 01 00 00 00 00 02 8c 00 15 01 00 00 00 00 02 90 00 15 01 00 00 00 00 02 91 40 15 01 00 00 00 00 02 92 0b 15 01 00 00 00 00 02 93 14 15 01 00 00 00 00 02 94 0f 15 01 00 00 00 00 02 95 03 15 01 00 00 00 00 02 98 0c 15 01 00 00 00 00 02 99 08 15 01 00 00 00 00 02 9a 08 15 01 00 00 00 00 02 a0 0b 15 01 00 00 00 00 02 a2 06 15 01 00 00 00 00 02 a3 06 15 01 00 00 00 00 02 aa 07 15 01 00 00 00 00 02 ab 02 15 01 00 00 00 00 02 b2 07 15 01 00 00 00 00 02 b3 05 15 01 00 00 00 00 02 ba 04 15 01 00 00 00 00 02 bb 03 15 01 00 00 00 00 02 bc 02 15 01 00 00 00 00 02 bd 03 15 01 00 00 00 00 02 c2 03 15 01 00 00 00 00 02 c3 03 15 01 00 00 00 00 02 c4 02 15 01 00 00 00 00 02 c9 02 15 01 00 00 00 00 02 ca 02 15 01 00 00 00 00 02 cb 01 15 01 00 00 00 00 02 da 70 15 01 00 00 00 00 02 db 30 15 01 00 00 00 00 02 dc 30 15 01 00 00 00 00 02 dd 1c 15 01 00 00 00 00 02 de 02 15 01 00 00 00 00 02 df 1b 15 01 00 00 00 00 02 e2 1f 15 01 00 00 00 00 02 e3 20 15 01 00 00 00 00 02 e4 18 15 01 00 00 00 00 02 ea 18 15 01 00 00 00 00 02 eb 10 15 01 00 00 00 00 02 ec 14 15 01 00 00 00 00 02 f3 0c 15 01 00 00 00 00 02 f4 06 15 01 00 00 00 00 02 fe 5b 15 01 00 00 00 00 02 01 10 15 01 00 00 00 00 02 02 08 15 01 00 00 00 00 02 03 04 15 01 00 00 00 00 02 09 06 15 01 00 00 00 00 02 0a 05 15 01 00 00 00 00 02 11 02 15 01 00 00 00 00 02 12 02 15 01 00 00 00 00 02 18 02 15 01 00 00 00 00 02 19 07 15 01 00 00 00 00 02 1b ff 15 01 00 00 00 00 02 21 02 15 01 00 00 00 00 02 22 01 15 01 00 00 00 00 02 23 01 15 01 00 00 00 00 02 24 01 15 01 00 00 00 00 02 25 02 15 01 00 00 00 00 02 29 10 15 01 00 00 00 00 02 2b 20 15 01 00 00 00 00 02 2d 1c 15 01 00 00 00 00 02 2f 10 15 01 00 00 00 00 02 30 22 15 01 00 00 00 00 02 33 f9 15 01 00 00 00 00 02 34 ff 15 01 00 00 00 00 02 35 00 15 01 00 00 00 00 02 3b f9 15 01 00 00 00 00 02 3d 00 15 01 00 00 00 00 02 45 fe 15 01 00 00 00 00 02 46 00 15 01 00 00 00 00 02 55 ff 15 01 00 00 00 00 02 56 fd 15 01 00 00 00 00 02 5e ff 15 01 00 00 00 00 02 5f 01 15 01 00 00 00 00 02 60 02 15 01 00 00 00 00 02 65 fe 15 01 00 00 00 00 02 66 01 15 01 00 00 00 00 02 67 fc 15 01 00 00 00 00 02 6e 01 15 01 00 00 00 00 02 6f 01 15 01 00 00 00 00 02 70 01 15 01 00 00 00 00 02 71 00 15 01 00 00 00 00 02 fe 9b 15 01 00 00 00 00 02 0b 4e 15 01 00 00 00 00 02 fe 00 15 01 00 00 00 00 02 c2 08 15 01 00 00 00 00 02 35 00 15 01 00 00 00 00 02 53 20 39 01 00 00 00 00 03 51 00 00 05 01 00 00 64 00 01 11 05 01 00 00 14 00 01 29];
						zte,mdss-dsi-bl-commands-state = "dsi_lp_mode";
						zte,mdss-dsi-dim-off-commands-state = "dsi_lp_mode";
						zte,mdss-dsi-dim-on-commands-state = "dsi_lp_mode";
						zte,mdss-dsi-hbm-off-aod-on-commands-state = "dsi_lp_mode";
						zte,mdss-dsi-reg-read-commands-state = "dsi_lp_mode";
						zte,mdss-dsi-aod-off-hbm-on-commands-state = "dsi_lp_mode";
						zte,mdss-dsi-restore-bl-commands-state = "dsi_lp_mode";
						zte,mdss-dsi-aod-high-commands-state = "dsi_lp_mode";
						zte,mdss-dsi-aod-mid-commands-state = "dsi_lp_mode";
						zte,mdss-dsi-aod-low-commands-state = "dsi_lp_mode";
						zte,mdss-dsi-hbm-off-commands-state = "dsi_lp_mode";
						zte,mdss-dsi-hbm-on-commands-state = "dsi_lp_mode";
						zte,mdss-dsi-bl-commands = [15 01 00 00 00 00 02 fe 00 39 01 00 00 00 00 03 51 03 ff];
						zte,mdss-dsi-dim-off-commands = [15 01 00 00 00 00 02 fe 00 15 01 00 00 00 00 02 53 20];
						zte,mdss-dsi-dim-on-commands = [15 01 00 00 00 00 02 fe 00 15 01 00 00 00 00 02 53 28];
						zte,mdss-dsi-hbm-off-aod-on-commands = [15 01 00 00 00 00 02 fe 00 39 01 00 00 00 00 03 51 00 00 05 01 00 00 00 00 01 39 39 01 00 00 00 00 03 51 01 20];
						zte,mdss-dsi-reg-read-commands = <0x6010000 0x1a0>;
						zte,mdss-dsi-aod-off-hbm-on-commands = [15 01 00 00 00 00 02 fe 00 05 01 00 00 00 00 01 38 39 01 00 00 00 00 03 51 1f fe];
						zte,mdss-dsi-acl-high-commands = [15 01 00 00 00 00 02 fe 00 15 01 00 00 00 00 02 55 11];
						zte,mdss-dsi-acl-mid-commands = [15 01 00 00 00 00 02 fe 00 15 01 00 00 00 00 02 55 12];
						zte,mdss-dsi-acl-low-commands = [15 01 00 00 00 00 02 fe 00 15 01 00 00 00 00 02 55 13];
						zte,mdss-dsi-acl-off-commands = [15 01 00 00 00 00 02 fe 00 15 01 00 00 00 00 02 55 10];
						zte,mdss-dsi-restore-bl-commands = [15 01 00 00 00 00 02 fe 00 39 01 00 00 00 00 03 51 03 ff];
						zte,mdss-dsi-aod-high-commands = [15 01 00 00 00 00 02 fe 00 39 01 00 00 00 00 03 51 1f fc];
						zte,mdss-dsi-aod-mid-commands = [15 01 00 00 00 00 02 fe 00 39 01 00 00 00 00 03 51 0a ae];
						zte,mdss-dsi-aod-low-commands = [15 01 00 00 00 00 02 fe 00 39 01 00 00 00 00 03 51 00 08];
						zte,mdss-dsi-hbm-off-commands = <0x15010000 0x2fe 0x390100 0x02 0x53203901 0x00 0x3510322>;
						zte,mdss-dsi-hbm-on-commands = <0x15010000 0x2fe 0x390100 0x02 0x53203901 0x00 0x3511ffe>;
						qcom,mdss-dsi-nolp-command-state = "dsi_lp_mode";
						qcom,mdss-dsi-nolp-command = [15 01 00 00 00 00 02 fe 00 39 01 00 00 00 00 03 51 00 00 05 01 00 00 00 00 01 38];
						qcom,mdss-dsi-lp1-command-state = "dsi_lp_mode";
						qcom,mdss-dsi-lp1-command = [15 01 00 00 00 00 02 fe 00 05 01 00 00 14 00 01 39];
						qcom,mdss-dsi-off-command-state = "dsi_lp_mode";
						qcom,mdss-dsi-off-command = [15 01 00 00 14 00 02 fe 00 05 01 00 00 10 00 01 28 05 01 00 00 78 00 01 10];
						qcom,default-topology-index = <0x00>;
						qcom,display-topology = <0x02 0x02 0x01>;
						qcom,mdss-dsc-block-prediction-enable;
						qcom,mdss-dsc-bit-per-pixel = <0x08>;
						qcom,mdss-dsc-bit-per-component = <0x0a>;
						qcom,mdss-dsc-slice-per-pkt = <0x02>;
						qcom,mdss-dsc-slice-width = <0x260>;
						qcom,mdss-dsc-slice-height = <0x10>;
						qcom,compression-mode = "dsc";
						qcom,mdss-mdp-transfer-time-us = <0x185b>;
						qcom,mdss-dsi-panel-framerate = <0x5a>;
						qcom,mdss-dsi-v-bottom-border = <0x00>;
						qcom,mdss-dsi-v-top-border = <0x00>;
						qcom,mdss-dsi-h-right-border = <0x00>;
						qcom,mdss-dsi-h-left-border = <0x00>;
						qcom,mdss-dsi-h-sync-pulse = <0x00>;
						qcom,mdss-dsi-v-pulse-width = <0x08>;
						qcom,mdss-dsi-v-front-porch = <0x38>;
						qcom,mdss-dsi-v-back-porch = <0x08>;
						qcom,mdss-dsi-h-sync-skew = <0x00>;
						qcom,mdss-dsi-h-pulse-width = <0x08>;
						qcom,mdss-dsi-h-back-porch = <0x80>;
						qcom,mdss-dsi-h-front-porch = <0x6c>;
						qcom,mdss-dsi-panel-height = <0xa80>;
						qcom,mdss-dsi-panel-width = <0x4c0>;
						cell-index = <0x01>;
					};

					timing@2 {
						qcom,mdss-dsi-panel-phy-timings = [00 23 09 09 1a 18 09 09 09 02 04 00 1d 0e];
						qcom,mdss-dsi-timing-switch-command-state = "dsi_lp_mode";
						qcom,mdss-dsi-timing-switch-command = [39 00 00 40 00 00 02 fe 00 39 00 00 40 00 00 02 2f 05 39 00 00 40 00 00 02 fe 5a 39 00 00 40 00 00 02 47 ff 39 00 00 40 00 00 02 48 f0 39 00 00 40 00 00 02 49 3a 39 00 00 40 00 00 02 4a 00 39 00 00 40 00 00 02 4b 10 39 00 00 40 00 00 02 4c fc 39 00 00 40 00 00 02 4f 22 39 00 00 40 00 00 02 50 30 39 00 00 40 00 00 02 51 00 39 00 00 40 00 00 02 53 08 39 00 00 40 00 00 02 58 05 39 00 00 40 00 00 02 59 00 39 00 00 40 00 00 02 60 00 39 00 00 40 00 00 02 61 00 39 00 00 40 00 00 02 68 f6 39 00 00 40 00 00 02 69 00 39 00 00 40 00 00 02 70 00 39 00 00 40 00 00 02 79 01 39 00 00 40 00 00 02 7a 00 39 00 00 40 00 00 02 7f 02 39 00 00 40 00 00 02 80 01 39 00 00 40 00 00 02 88 00 39 00 00 40 00 00 02 89 00 39 00 00 40 00 00 02 8a 00 39 00 00 40 00 00 02 8c ff 39 00 00 40 00 00 02 90 00 39 00 00 40 00 00 02 91 30 39 00 00 40 00 00 02 92 10 39 00 00 40 00 00 02 93 10 39 00 00 40 00 00 02 94 09 39 00 00 40 00 00 02 95 1d 39 00 00 40 00 00 02 98 0e 39 00 00 40 00 00 02 99 16 39 00 00 40 00 00 02 9a 10 39 00 00 40 00 00 02 a0 10 39 00 00 40 00 00 02 a2 09 39 00 00 40 00 00 02 a3 06 39 00 00 40 00 00 02 aa 00 39 00 00 40 00 00 02 ab 00 39 00 00 40 00 00 02 b2 07 39 00 00 40 00 00 02 b3 03 39 00 00 40 00 00 02 ba 01 39 00 00 40 00 00 02 bb 01 39 00 00 40 00 00 02 bc 02 39 00 00 40 00 00 02 bd 00 39 00 00 40 00 00 02 c2 04 39 00 00 40 00 00 02 c3 04 39 00 00 40 00 00 02 c4 02 39 00 00 40 00 00 02 c9 05 39 00 00 40 00 00 02 ca 01 39 00 00 40 00 00 02 cb 01 39 00 00 40 00 00 02 da 70 39 00 00 40 00 00 02 db 4c 39 00 00 40 00 00 02 dc 3f 39 00 00 40 00 00 02 dd 15 39 00 00 40 00 00 02 de 12 39 00 00 40 00 00 02 df 1b 39 00 00 40 00 00 02 e2 23 39 00 00 40 00 00 02 e3 3c 39 00 00 40 00 00 02 e4 28 39 00 00 40 00 00 02 ea 1f 39 00 00 40 00 00 02 eb 1a 39 00 00 40 00 00 02 ec 14 39 00 00 40 00 00 02 f3 10 39 00 00 40 00 00 02 f4 08 39 00 00 40 00 00 02 fe 5b 39 00 00 40 00 00 02 01 12 39 00 00 40 00 00 02 02 0b 39 00 00 40 00 00 02 03 04 39 00 00 40 00 00 02 09 08 39 00 00 40 00 00 02 0a 05 39 00 00 40 00 00 02 11 08 39 00 00 40 00 00 02 12 05 39 00 00 40 00 00 02 18 0a 39 00 00 40 00 00 02 19 05 39 00 00 40 00 00 02 1b 00 39 00 00 40 00 00 02 21 03 39 00 00 40 00 00 02 22 02 39 00 00 40 00 00 02 23 02 39 00 00 40 00 00 02 24 02 39 00 00 40 00 00 02 25 04 39 00 00 40 00 00 02 29 10 39 00 00 40 00 00 02 2b dc 39 00 00 40 00 00 02 2d 1f 39 00 00 40 00 00 02 2f fc 39 00 00 40 00 00 02 30 22 39 00 00 40 00 00 02 33 f8 39 00 00 40 00 00 02 34 e0 39 00 00 40 00 00 02 35 00 39 00 00 40 00 00 02 3b f9 39 00 00 40 00 00 02 3d ff 39 00 00 40 00 00 02 45 00 39 00 00 40 00 00 02 46 ff 39 00 00 40 00 00 02 55 00 39 00 00 40 00 00 02 56 fc 39 00 00 40 00 00 02 5e fe 39 00 00 40 00 00 02 5f ff 39 00 00 40 00 00 02 60 02 39 00 00 40 00 00 02 65 fa 39 00 00 40 00 00 02 66 ff 39 00 00 40 00 00 02 67 ff 39 00 00 40 00 00 02 6e 00 39 00 00 40 00 00 02 6f 00 39 00 00 40 00 00 02 70 00 39 00 00 40 00 00 02 71 01 39 00 00 00 00 00 02 fe 00];
						qcom,mdss-dsi-on-command-state = "dsi_lp_mode";
						qcom,mdss-dsi-on-command = [15 01 00 00 00 00 02 fe d4 15 01 00 00 00 00 02 40 03 15 01 00 00 00 00 02 fe fd 15 01 00 00 00 00 02 80 06 15 01 00 00 00 00 02 83 00 15 01 00 00 00 00 02 ee 00 15 01 00 00 00 00 02 ef 00 15 01 00 00 00 00 02 fe d0 15 01 00 00 00 00 02 7e 80 15 01 00 00 00 00 02 fe b6 15 01 00 00 00 00 02 01 74 15 01 00 00 00 00 02 fe a1 15 01 00 00 00 00 02 74 72 15 01 00 00 00 00 02 c3 c3 15 01 00 00 00 00 02 c4 ff 15 01 00 00 00 00 02 c5 7f 15 01 00 00 00 00 02 fe 00 15 01 00 00 00 00 02 fa 01 15 01 00 00 00 00 02 fe d2 15 01 00 00 00 00 02 97 08 15 01 00 00 00 00 02 36 11 15 01 00 00 00 00 02 39 ab 15 01 00 00 00 00 02 3a 30 15 01 00 00 00 00 02 3b 80 15 01 00 00 00 00 02 3d 0a 15 01 00 00 00 00 02 3f 80 15 01 00 00 00 00 02 40 04 15 01 00 00 00 00 02 41 c0 15 01 00 00 00 00 02 42 00 15 01 00 00 00 00 02 43 10 15 01 00 00 00 00 02 44 02 15 01 00 00 00 00 02 45 60 15 01 00 00 00 00 02 46 02 15 01 00 00 00 00 02 47 60 15 01 00 00 00 00 02 48 02 15 01 00 00 00 00 02 49 00 15 01 00 00 00 00 02 4a 02 15 01 00 00 00 00 02 4b 31 15 01 00 00 00 00 02 4d 20 15 01 00 00 00 00 02 4e 01 15 01 00 00 00 00 02 4f 68 15 01 00 00 00 00 02 50 00 15 01 00 00 00 00 02 51 08 15 01 00 00 00 00 02 53 0c 15 01 00 00 00 00 02 54 06 15 01 00 00 00 00 02 55 67 15 01 00 00 00 00 02 56 05 15 01 00 00 00 00 02 58 ad 15 01 00 00 00 00 02 59 18 15 01 00 00 00 00 02 5a 00 15 01 00 00 00 00 02 5b 11 15 01 00 00 00 00 02 5c 00 15 01 00 00 00 00 02 5d 07 15 01 00 00 00 00 02 5e 10 15 01 00 00 00 00 02 5f 20 15 01 00 00 00 00 02 60 00 15 01 00 00 00 00 02 61 06 15 01 00 00 00 00 02 62 0f 15 01 00 00 00 00 02 63 0f 15 01 00 00 00 00 02 64 33 15 01 00 00 00 00 02 65 0e 15 01 00 00 00 00 02 66 1c 15 01 00 00 00 00 02 67 2a 15 01 00 00 00 00 02 68 38 15 01 00 00 00 00 02 69 46 15 01 00 00 00 00 02 6a 54 15 01 00 00 00 00 02 6b 62 15 01 00 00 00 00 02 6c 69 15 01 00 00 00 00 02 6d 70 15 01 00 00 00 00 02 6e 77 15 01 00 00 00 00 02 6f 79 15 01 00 00 00 00 02 70 7b 15 01 00 00 00 00 02 71 7d 15 01 00 00 00 00 02 72 7e 15 01 00 00 00 00 02 73 02 15 01 00 00 00 00 02 74 02 15 01 00 00 00 00 02 75 22 15 01 00 00 00 00 02 76 00 15 01 00 00 00 00 02 77 2a 15 01 00 00 00 00 02 78 40 15 01 00 00 00 00 02 79 2a 15 01 00 00 00 00 02 7a be 15 01 00 00 00 00 02 7b 3a 15 01 00 00 00 00 02 7c fc 15 01 00 00 00 00 02 7d 3a 15 01 00 00 00 00 02 7e fa 15 01 00 00 00 00 02 7f 3a 15 01 00 00 00 00 02 80 f8 15 01 00 00 00 00 02 81 3b 15 01 00 00 00 00 02 82 38 15 01 00 00 00 00 02 83 3b 15 01 00 00 00 00 02 84 78 15 01 00 00 00 00 02 85 3b 15 01 00 00 00 00 02 86 b6 15 01 00 00 00 00 02 87 4b 15 01 00 00 00 00 02 88 f6 15 01 00 00 00 00 02 89 4c 15 01 00 00 00 00 02 8a 34 15 01 00 00 00 00 02 8b 4c 15 01 00 00 00 00 02 8c 74 15 01 00 00 00 00 02 8d 5c 15 01 00 00 00 00 02 8e 74 15 01 00 00 00 00 02 8f 8c 15 01 00 00 00 00 02 90 f4 15 01 00 00 00 00 02 91 00 15 01 00 00 00 00 02 92 00 15 01 00 00 00 00 02 93 00 15 01 00 00 00 00 02 94 00 15 01 00 00 00 00 02 95 00 15 01 00 00 00 00 02 96 00 15 01 00 00 00 00 02 fe 34 15 01 00 00 00 00 02 82 c0 15 01 00 00 00 00 02 83 04 15 01 00 00 00 00 02 00 08 15 01 00 00 00 00 02 1c 00 15 01 00 00 00 00 02 1d 10 15 01 00 00 00 00 02 49 05 15 01 00 00 00 00 02 1e 00 15 01 00 00 00 00 02 1f 00 15 01 00 00 00 00 02 20 00 15 01 00 00 00 00 02 21 70 15 01 00 00 00 00 02 22 00 15 01 00 00 00 00 02 23 f8 15 01 00 00 00 00 02 24 77 15 01 00 00 00 00 02 25 f8 15 01 00 00 00 00 02 26 f8 15 01 00 00 00 00 02 2f 00 15 01 00 00 00 00 02 30 00 15 01 00 00 00 00 02 31 00 15 01 00 00 00 00 02 32 00 15 01 00 00 00 00 02 33 00 15 01 00 00 00 00 02 34 00 15 01 00 00 00 00 02 35 00 15 01 00 00 00 00 02 36 c4 15 01 00 00 00 00 02 37 00 15 01 00 00 00 00 02 38 87 15 01 00 00 00 00 02 39 00 15 01 00 00 00 00 02 3a 4b 15 01 00 00 00 00 02 3b 00 15 01 00 00 00 00 02 3d 00 15 01 00 00 00 00 02 3f 00 15 01 00 00 00 00 02 40 00 15 01 00 00 00 00 02 41 00 15 01 00 00 00 00 02 42 00 15 01 00 00 00 00 02 54 03 15 01 00 00 00 00 02 55 77 15 01 00 00 00 00 02 56 f8 15 01 00 00 00 00 02 58 f8 15 01 00 00 00 00 02 59 77 15 01 00 00 00 00 02 5a f8 15 01 00 00 00 00 02 5b f8 15 01 00 00 00 00 02 5c 77 15 01 00 00 00 00 02 5d f8 15 01 00 00 00 00 02 5e f8 15 01 00 00 00 00 02 5f 77 15 01 00 00 00 00 02 60 f8 15 01 00 00 00 00 02 61 f8 15 01 00 00 00 00 02 62 77 15 01 00 00 00 00 02 63 f8 15 01 00 00 00 00 02 64 f8 15 01 00 00 00 00 02 65 77 15 01 00 00 00 00 02 66 f8 15 01 00 00 00 00 02 67 f8 15 01 00 00 00 00 02 77 07 15 01 00 00 00 00 02 78 f8 15 01 00 00 00 00 02 fe 00 15 01 00 00 00 00 02 2f 05 15 01 00 00 00 00 02 fe 5a 15 01 00 00 00 00 02 47 ff 15 01 00 00 00 00 02 48 f0 15 01 00 00 00 00 02 49 3a 15 01 00 00 00 00 02 4a 00 15 01 00 00 00 00 02 4b 10 15 01 00 00 00 00 02 4c fc 15 01 00 00 00 00 02 4f 22 15 01 00 00 00 00 02 50 30 15 01 00 00 00 00 02 51 00 15 01 00 00 00 00 02 53 08 15 01 00 00 00 00 02 58 05 15 01 00 00 00 00 02 59 00 15 01 00 00 00 00 02 60 00 15 01 00 00 00 00 02 61 00 15 01 00 00 00 00 02 68 f6 15 01 00 00 00 00 02 69 00 15 01 00 00 00 00 02 70 00 15 01 00 00 00 00 02 79 01 15 01 00 00 00 00 02 7a 00 15 01 00 00 00 00 02 7f 02 15 01 00 00 00 00 02 80 01 15 01 00 00 00 00 02 88 00 15 01 00 00 00 00 02 89 00 15 01 00 00 00 00 02 8a 00 15 01 00 00 00 00 02 8c ff 15 01 00 00 00 00 02 90 00 15 01 00 00 00 00 02 91 30 15 01 00 00 00 00 02 92 10 15 01 00 00 00 00 02 93 10 15 01 00 00 00 00 02 94 09 15 01 00 00 00 00 02 95 1d 15 01 00 00 00 00 02 98 0e 15 01 00 00 00 00 02 99 16 15 01 00 00 00 00 02 9a 10 15 01 00 00 00 00 02 a0 10 15 01 00 00 00 00 02 a2 09 15 01 00 00 00 00 02 a3 06 15 01 00 00 00 00 02 aa 00 15 01 00 00 00 00 02 ab 00 15 01 00 00 00 00 02 b2 07 15 01 00 00 00 00 02 b3 03 15 01 00 00 00 00 02 ba 01 15 01 00 00 00 00 02 bb 01 15 01 00 00 00 00 02 bc 02 15 01 00 00 00 00 02 bd 00 15 01 00 00 00 00 02 c2 04 15 01 00 00 00 00 02 c3 04 15 01 00 00 00 00 02 c4 02 15 01 00 00 00 00 02 c9 05 15 01 00 00 00 00 02 ca 01 15 01 00 00 00 00 02 cb 01 15 01 00 00 00 00 02 da 70 15 01 00 00 00 00 02 db 4c 15 01 00 00 00 00 02 dc 3f 15 01 00 00 00 00 02 dd 15 15 01 00 00 00 00 02 de 12 15 01 00 00 00 00 02 df 1b 15 01 00 00 00 00 02 e2 23 15 01 00 00 00 00 02 e3 3c 15 01 00 00 00 00 02 e4 28 15 01 00 00 00 00 02 ea 1f 15 01 00 00 00 00 02 eb 1a 15 01 00 00 00 00 02 ec 14 15 01 00 00 00 00 02 f3 10 15 01 00 00 00 00 02 f4 08 15 01 00 00 00 00 02 fe 5b 15 01 00 00 00 00 02 01 12 15 01 00 00 00 00 02 02 0b 15 01 00 00 00 00 02 03 04 15 01 00 00 00 00 02 09 08 15 01 00 00 00 00 02 0a 05 15 01 00 00 00 00 02 11 08 15 01 00 00 00 00 02 12 05 15 01 00 00 00 00 02 18 0a 15 01 00 00 00 00 02 19 05 15 01 00 00 00 00 02 1b 00 15 01 00 00 00 00 02 21 03 15 01 00 00 00 00 02 22 02 15 01 00 00 00 00 02 23 02 15 01 00 00 00 00 02 24 02 15 01 00 00 00 00 02 25 04 15 01 00 00 00 00 02 29 10 15 01 00 00 00 00 02 2b dc 15 01 00 00 00 00 02 2d 1f 15 01 00 00 00 00 02 2f fc 15 01 00 00 00 00 02 30 22 15 01 00 00 00 00 02 33 f8 15 01 00 00 00 00 02 34 e0 15 01 00 00 00 00 02 35 00 15 01 00 00 00 00 02 3b f9 15 01 00 00 00 00 02 3d ff 15 01 00 00 00 00 02 45 00 15 01 00 00 00 00 02 46 ff 15 01 00 00 00 00 02 55 00 15 01 00 00 00 00 02 56 fc 15 01 00 00 00 00 02 5e fe 15 01 00 00 00 00 02 5f ff 15 01 00 00 00 00 02 60 02 15 01 00 00 00 00 02 65 fa 15 01 00 00 00 00 02 66 ff 15 01 00 00 00 00 02 67 ff 15 01 00 00 00 00 02 6e 00 15 01 00 00 00 00 02 6f 00 15 01 00 00 00 00 02 70 00 15 01 00 00 00 00 02 71 01 15 01 00 00 00 00 02 fe 9b 15 01 00 00 00 00 02 0b 4e 15 01 00 00 00 00 02 fe 00 15 01 00 00 00 00 02 c2 08 15 01 00 00 00 00 02 35 00 15 01 00 00 00 00 02 53 20 39 01 00 00 00 00 03 51 00 00 05 01 00 00 64 00 01 11 05 01 00 00 14 00 01 29];
						zte,mdss-dsi-bl-commands-state = "dsi_lp_mode";
						zte,mdss-dsi-dim-off-commands-state = "dsi_lp_mode";
						zte,mdss-dsi-dim-on-commands-state = "dsi_lp_mode";
						zte,mdss-dsi-hbm-off-aod-on-commands-state = "dsi_lp_mode";
						zte,mdss-dsi-reg-read-commands-state = "dsi_lp_mode";
						zte,mdss-dsi-aod-off-hbm-on-commands-state = "dsi_lp_mode";
						zte,mdss-dsi-restore-bl-commands-state = "dsi_lp_mode";
						zte,mdss-dsi-aod-high-commands-state = "dsi_lp_mode";
						zte,mdss-dsi-aod-mid-commands-state = "dsi_lp_mode";
						zte,mdss-dsi-aod-low-commands-state = "dsi_lp_mode";
						zte,mdss-dsi-hbm-off-commands-state = "dsi_lp_mode";
						zte,mdss-dsi-hbm-on-commands-state = "dsi_lp_mode";
						zte,mdss-dsi-bl-commands = [15 01 00 00 00 00 02 fe 00 39 01 00 00 00 00 03 51 03 ff];
						zte,mdss-dsi-dim-off-commands = [15 01 00 00 00 00 02 fe 00 15 01 00 00 00 00 02 53 20];
						zte,mdss-dsi-dim-on-commands = [15 01 00 00 00 00 02 fe 00 15 01 00 00 00 00 02 53 28];
						zte,mdss-dsi-hbm-off-aod-on-commands = [15 01 00 00 00 00 02 fe 00 39 01 00 00 00 00 03 51 00 00 05 01 00 00 00 00 01 39 39 01 00 00 00 00 03 51 01 20];
						zte,mdss-dsi-reg-read-commands = <0x6010000 0x1a0>;
						zte,mdss-dsi-aod-off-hbm-on-commands = [15 01 00 00 00 00 02 fe 00 05 01 00 00 00 00 01 38 39 01 00 00 00 00 03 51 1f fe];
						zte,mdss-dsi-acl-high-commands = [15 01 00 00 00 00 02 fe 00 15 01 00 00 00 00 02 55 11];
						zte,mdss-dsi-acl-mid-commands = [15 01 00 00 00 00 02 fe 00 15 01 00 00 00 00 02 55 12];
						zte,mdss-dsi-acl-low-commands = [15 01 00 00 00 00 02 fe 00 15 01 00 00 00 00 02 55 13];
						zte,mdss-dsi-acl-off-commands = [15 01 00 00 00 00 02 fe 00 15 01 00 00 00 00 02 55 10];
						zte,mdss-dsi-restore-bl-commands = [15 01 00 00 00 00 02 fe 00 39 01 00 00 00 00 03 51 03 ff];
						zte,mdss-dsi-aod-high-commands = [15 01 00 00 00 00 02 fe 00 39 01 00 00 00 00 03 51 1f fc];
						zte,mdss-dsi-aod-mid-commands = [15 01 00 00 00 00 02 fe 00 39 01 00 00 00 00 03 51 0a ae];
						zte,mdss-dsi-aod-low-commands = [15 01 00 00 00 00 02 fe 00 39 01 00 00 00 00 03 51 00 08];
						zte,mdss-dsi-hbm-off-commands = <0x15010000 0x2fe 0x390100 0x02 0x53203901 0x00 0x3510322>;
						zte,mdss-dsi-hbm-on-commands = <0x15010000 0x2fe 0x390100 0x02 0x53203901 0x00 0x3511ffe>;
						qcom,mdss-dsi-nolp-command-state = "dsi_lp_mode";
						qcom,mdss-dsi-nolp-command = [15 01 00 00 00 00 02 fe 00 39 01 00 00 00 00 03 51 00 00 05 01 00 00 00 00 01 38];
						qcom,mdss-dsi-lp1-command-state = "dsi_lp_mode";
						qcom,mdss-dsi-lp1-command = [15 01 00 00 00 00 02 fe 00 05 01 00 00 14 00 01 39];
						qcom,mdss-dsi-off-command-state = "dsi_lp_mode";
						qcom,mdss-dsi-off-command = [15 01 00 00 14 00 02 fe 00 05 01 00 00 10 00 01 28 05 01 00 00 78 00 01 10];
						qcom,default-topology-index = <0x00>;
						qcom,display-topology = <0x02 0x02 0x01>;
						qcom,mdss-dsc-block-prediction-enable;
						qcom,mdss-dsc-bit-per-pixel = <0x08>;
						qcom,mdss-dsc-bit-per-component = <0x0a>;
						qcom,mdss-dsc-slice-per-pkt = <0x02>;
						qcom,mdss-dsc-slice-width = <0x260>;
						qcom,mdss-dsc-slice-height = <0x10>;
						qcom,compression-mode = "dsc";
						qcom,mdss-mdp-transfer-time-us = <0x185b>;
						qcom,mdss-dsi-panel-framerate = <0x78>;
						qcom,mdss-dsi-v-bottom-border = <0x00>;
						qcom,mdss-dsi-v-top-border = <0x00>;
						qcom,mdss-dsi-h-right-border = <0x00>;
						qcom,mdss-dsi-h-left-border = <0x00>;
						qcom,mdss-dsi-h-sync-pulse = <0x00>;
						qcom,mdss-dsi-v-pulse-width = <0x08>;
						qcom,mdss-dsi-v-front-porch = <0x38>;
						qcom,mdss-dsi-v-back-porch = <0x08>;
						qcom,mdss-dsi-h-sync-skew = <0x00>;
						qcom,mdss-dsi-h-pulse-width = <0x08>;
						qcom,mdss-dsi-h-back-porch = <0x3c>;
						qcom,mdss-dsi-h-front-porch = <0x20>;
						qcom,mdss-dsi-panel-height = <0xa80>;
						qcom,mdss-dsi-panel-width = <0x4c0>;
						cell-index = <0x02>;
					};

					timing@3 {
						qcom,mdss-dsi-panel-phy-timings = [00 23 09 09 1a 18 09 09 09 02 04 00 1d 0e];
						qcom,mdss-dsi-timing-switch-command-state = "dsi_lp_mode";
						qcom,mdss-dsi-timing-switch-command = [39 00 00 40 00 00 02 fe 00 39 00 00 40 00 00 02 2f 00 39 00 00 40 00 00 02 fe 5a 39 00 00 40 00 00 02 47 ff 39 00 00 40 00 00 02 48 f0 39 00 00 40 00 00 02 49 3a 39 00 00 40 00 00 02 4a 00 39 00 00 40 00 00 02 4b 10 39 00 00 40 00 00 02 4c fc 39 00 00 40 00 00 02 4f 22 39 00 00 40 00 00 02 50 30 39 00 00 40 00 00 02 51 00 39 00 00 40 00 00 02 53 06 39 00 00 40 00 00 02 58 05 39 00 00 40 00 00 02 59 00 39 00 00 40 00 00 02 60 00 39 00 00 40 00 00 02 61 00 39 00 00 40 00 00 02 68 f6 39 00 00 40 00 00 02 69 00 39 00 00 40 00 00 02 70 00 39 00 00 40 00 00 02 79 01 39 00 00 40 00 00 02 7a 00 39 00 00 40 00 00 02 7f 02 39 00 00 40 00 00 02 80 01 39 00 00 40 00 00 02 88 00 39 00 00 40 00 00 02 89 00 39 00 00 40 00 00 02 8a 00 39 00 00 40 00 00 02 8c ff 39 00 00 40 00 00 02 90 00 39 00 00 40 00 00 02 91 30 39 00 00 40 00 00 02 92 10 39 00 00 40 00 00 02 93 10 39 00 00 40 00 00 02 94 09 39 00 00 40 00 00 02 95 1d 39 00 00 40 00 00 02 98 0e 39 00 00 40 00 00 02 99 20 39 00 00 40 00 00 02 9a 10 39 00 00 40 00 00 02 a0 10 39 00 00 40 00 00 02 a2 09 39 00 00 40 00 00 02 a3 06 39 00 00 40 00 00 02 aa 00 39 00 00 40 00 00 02 ab 02 39 00 00 40 00 00 02 b2 07 39 00 00 40 00 00 02 b3 02 39 00 00 40 00 00 02 ba 01 39 00 00 40 00 00 02 bb 01 39 00 00 40 00 00 02 bc 02 39 00 00 40 00 00 02 bd 00 39 00 00 40 00 00 02 c2 04 39 00 00 40 00 00 02 c3 04 39 00 00 40 00 00 02 c4 02 39 00 00 40 00 00 02 c9 05 39 00 00 40 00 00 02 ca 01 39 00 00 40 00 00 02 cb 01 39 00 00 40 00 00 02 da 70 39 00 00 40 00 00 02 db 4c 39 00 00 40 00 00 02 dc 38 39 00 00 40 00 00 02 dd 15 39 00 00 40 00 00 02 de 12 39 00 00 40 00 00 02 df 1b 39 00 00 40 00 00 02 e2 23 39 00 00 40 00 00 02 e3 3c 39 00 00 40 00 00 02 e4 28 39 00 00 40 00 00 02 ea 1f 39 00 00 40 00 00 02 eb 1a 39 00 00 40 00 00 02 ec 14 39 00 00 40 00 00 02 f3 10 39 00 00 40 00 00 02 f4 0d 39 00 00 40 00 00 02 fe 5b 39 00 00 40 00 00 02 01 12 39 00 00 40 00 00 02 02 0b 39 00 00 40 00 00 02 03 04 39 00 00 40 00 00 02 09 08 39 00 00 40 00 00 02 0a 05 39 00 00 40 00 00 02 11 08 39 00 00 40 00 00 02 12 05 39 00 00 40 00 00 02 18 0a 39 00 00 40 00 00 02 19 05 39 00 00 40 00 00 02 1b 00 39 00 00 40 00 00 02 21 03 39 00 00 40 00 00 02 22 02 39 00 00 40 00 00 02 23 02 39 00 00 40 00 00 02 24 02 39 00 00 40 00 00 02 25 04 39 00 00 40 00 00 02 29 10 39 00 00 40 00 00 02 2a ff 39 00 00 40 00 00 02 2b dc 39 00 00 40 00 00 02 2d 1f 39 00 00 40 00 00 02 2f fc 39 00 00 40 00 00 02 30 22 39 00 00 40 00 00 02 33 f8 39 00 00 40 00 00 02 34 e0 39 00 00 40 00 00 02 35 00 39 00 00 40 00 00 02 37 06 39 00 00 40 00 00 02 3b f9 39 00 00 40 00 00 02 3d ff 39 00 00 40 00 00 02 45 00 39 00 00 40 00 00 02 46 ff 39 00 00 40 00 00 02 55 00 39 00 00 40 00 00 02 56 00 39 00 00 40 00 00 02 5e fe 39 00 00 40 00 00 02 5f ff 39 00 00 40 00 00 02 60 02 39 00 00 40 00 00 02 65 fa 39 00 00 40 00 00 02 66 ff 39 00 00 40 00 00 02 67 ff 39 00 00 40 00 00 02 6e 00 39 00 00 40 00 00 02 6f 00 39 00 00 40 00 00 02 70 00 39 00 00 40 00 00 02 71 01 39 00 00 00 00 00 02 fe 00];
						qcom,mdss-dsi-on-command-state = "dsi_lp_mode";
						qcom,mdss-dsi-on-command = [15 01 00 00 00 00 02 fe d4 15 01 00 00 00 00 02 40 03 15 01 00 00 00 00 02 fe fd 15 01 00 00 00 00 02 80 06 15 01 00 00 00 00 02 83 00 15 01 00 00 00 00 02 ee 00 15 01 00 00 00 00 02 ef 00 15 01 00 00 00 00 02 fe d0 15 01 00 00 00 00 02 7e 80 15 01 00 00 00 00 02 fe b6 15 01 00 00 00 00 02 01 74 15 01 00 00 00 00 02 fe a1 15 01 00 00 00 00 02 74 72 15 01 00 00 00 00 02 c3 c3 15 01 00 00 00 00 02 c4 ff 15 01 00 00 00 00 02 c5 7f 15 01 00 00 00 00 02 fe 00 15 01 00 00 00 00 02 fa 01 15 01 00 00 00 00 02 fe d2 15 01 00 00 00 00 02 97 08 15 01 00 00 00 00 02 36 11 15 01 00 00 00 00 02 39 ab 15 01 00 00 00 00 02 3a 30 15 01 00 00 00 00 02 3b 80 15 01 00 00 00 00 02 3d 0a 15 01 00 00 00 00 02 3f 80 15 01 00 00 00 00 02 40 04 15 01 00 00 00 00 02 41 c0 15 01 00 00 00 00 02 42 00 15 01 00 00 00 00 02 43 10 15 01 00 00 00 00 02 44 02 15 01 00 00 00 00 02 45 60 15 01 00 00 00 00 02 46 02 15 01 00 00 00 00 02 47 60 15 01 00 00 00 00 02 48 02 15 01 00 00 00 00 02 49 00 15 01 00 00 00 00 02 4a 02 15 01 00 00 00 00 02 4b 31 15 01 00 00 00 00 02 4d 20 15 01 00 00 00 00 02 4e 01 15 01 00 00 00 00 02 4f 68 15 01 00 00 00 00 02 50 00 15 01 00 00 00 00 02 51 08 15 01 00 00 00 00 02 53 0c 15 01 00 00 00 00 02 54 06 15 01 00 00 00 00 02 55 67 15 01 00 00 00 00 02 56 05 15 01 00 00 00 00 02 58 ad 15 01 00 00 00 00 02 59 18 15 01 00 00 00 00 02 5a 00 15 01 00 00 00 00 02 5b 11 15 01 00 00 00 00 02 5c 00 15 01 00 00 00 00 02 5d 07 15 01 00 00 00 00 02 5e 10 15 01 00 00 00 00 02 5f 20 15 01 00 00 00 00 02 60 00 15 01 00 00 00 00 02 61 06 15 01 00 00 00 00 02 62 0f 15 01 00 00 00 00 02 63 0f 15 01 00 00 00 00 02 64 33 15 01 00 00 00 00 02 65 0e 15 01 00 00 00 00 02 66 1c 15 01 00 00 00 00 02 67 2a 15 01 00 00 00 00 02 68 38 15 01 00 00 00 00 02 69 46 15 01 00 00 00 00 02 6a 54 15 01 00 00 00 00 02 6b 62 15 01 00 00 00 00 02 6c 69 15 01 00 00 00 00 02 6d 70 15 01 00 00 00 00 02 6e 77 15 01 00 00 00 00 02 6f 79 15 01 00 00 00 00 02 70 7b 15 01 00 00 00 00 02 71 7d 15 01 00 00 00 00 02 72 7e 15 01 00 00 00 00 02 73 02 15 01 00 00 00 00 02 74 02 15 01 00 00 00 00 02 75 22 15 01 00 00 00 00 02 76 00 15 01 00 00 00 00 02 77 2a 15 01 00 00 00 00 02 78 40 15 01 00 00 00 00 02 79 2a 15 01 00 00 00 00 02 7a be 15 01 00 00 00 00 02 7b 3a 15 01 00 00 00 00 02 7c fc 15 01 00 00 00 00 02 7d 3a 15 01 00 00 00 00 02 7e fa 15 01 00 00 00 00 02 7f 3a 15 01 00 00 00 00 02 80 f8 15 01 00 00 00 00 02 81 3b 15 01 00 00 00 00 02 82 38 15 01 00 00 00 00 02 83 3b 15 01 00 00 00 00 02 84 78 15 01 00 00 00 00 02 85 3b 15 01 00 00 00 00 02 86 b6 15 01 00 00 00 00 02 87 4b 15 01 00 00 00 00 02 88 f6 15 01 00 00 00 00 02 89 4c 15 01 00 00 00 00 02 8a 34 15 01 00 00 00 00 02 8b 4c 15 01 00 00 00 00 02 8c 74 15 01 00 00 00 00 02 8d 5c 15 01 00 00 00 00 02 8e 74 15 01 00 00 00 00 02 8f 8c 15 01 00 00 00 00 02 90 f4 15 01 00 00 00 00 02 91 00 15 01 00 00 00 00 02 92 00 15 01 00 00 00 00 02 93 00 15 01 00 00 00 00 02 94 00 15 01 00 00 00 00 02 95 00 15 01 00 00 00 00 02 96 00 15 01 00 00 00 00 02 fe 34 15 01 00 00 00 00 02 82 c0 15 01 00 00 00 00 02 83 04 15 01 00 00 00 00 02 00 08 15 01 00 00 00 00 02 1c 00 15 01 00 00 00 00 02 1d 10 15 01 00 00 00 00 02 49 05 15 01 00 00 00 00 02 1e 00 15 01 00 00 00 00 02 1f 00 15 01 00 00 00 00 02 20 00 15 01 00 00 00 00 02 21 70 15 01 00 00 00 00 02 22 00 15 01 00 00 00 00 02 23 f8 15 01 00 00 00 00 02 24 77 15 01 00 00 00 00 02 25 f8 15 01 00 00 00 00 02 26 f8 15 01 00 00 00 00 02 2f 00 15 01 00 00 00 00 02 30 00 15 01 00 00 00 00 02 31 00 15 01 00 00 00 00 02 32 00 15 01 00 00 00 00 02 33 00 15 01 00 00 00 00 02 34 00 15 01 00 00 00 00 02 35 00 15 01 00 00 00 00 02 36 c4 15 01 00 00 00 00 02 37 00 15 01 00 00 00 00 02 38 87 15 01 00 00 00 00 02 39 00 15 01 00 00 00 00 02 3a 4b 15 01 00 00 00 00 02 3b 00 15 01 00 00 00 00 02 3d 00 15 01 00 00 00 00 02 3f 00 15 01 00 00 00 00 02 40 00 15 01 00 00 00 00 02 41 00 15 01 00 00 00 00 02 42 00 15 01 00 00 00 00 02 54 03 15 01 00 00 00 00 02 55 77 15 01 00 00 00 00 02 56 f8 15 01 00 00 00 00 02 58 f8 15 01 00 00 00 00 02 59 77 15 01 00 00 00 00 02 5a f8 15 01 00 00 00 00 02 5b f8 15 01 00 00 00 00 02 5c 77 15 01 00 00 00 00 02 5d f8 15 01 00 00 00 00 02 5e f8 15 01 00 00 00 00 02 5f 77 15 01 00 00 00 00 02 60 f8 15 01 00 00 00 00 02 61 f8 15 01 00 00 00 00 02 62 77 15 01 00 00 00 00 02 63 f8 15 01 00 00 00 00 02 64 f8 15 01 00 00 00 00 02 65 77 15 01 00 00 00 00 02 66 f8 15 01 00 00 00 00 02 67 f8 15 01 00 00 00 00 02 77 07 15 01 00 00 00 00 02 78 f8 15 01 00 00 00 00 02 fe 00 15 01 00 00 00 00 02 2f 00 15 01 00 00 00 00 02 fe 5a 15 01 00 00 00 00 02 47 ff 15 01 00 00 00 00 02 48 f0 15 01 00 00 00 00 02 49 3a 15 01 00 00 00 00 02 4a 00 15 01 00 00 00 00 02 4b 10 15 01 00 00 00 00 02 4c fc 15 01 00 00 00 00 02 4f 22 15 01 00 00 00 00 02 50 30 15 01 00 00 00 00 02 51 00 15 01 00 00 00 00 02 53 06 15 01 00 00 00 00 02 58 05 15 01 00 00 00 00 02 59 00 15 01 00 00 00 00 02 60 00 15 01 00 00 00 00 02 61 00 15 01 00 00 00 00 02 68 f6 15 01 00 00 00 00 02 69 00 15 01 00 00 00 00 02 70 00 15 01 00 00 00 00 02 79 01 15 01 00 00 00 00 02 7a 00 15 01 00 00 00 00 02 7f 02 15 01 00 00 00 00 02 80 01 15 01 00 00 00 00 02 88 00 15 01 00 00 00 00 02 89 00 15 01 00 00 00 00 02 8a 00 15 01 00 00 00 00 02 8c ff 15 01 00 00 00 00 02 90 00 15 01 00 00 00 00 02 91 30 15 01 00 00 00 00 02 92 10 15 01 00 00 00 00 02 93 10 15 01 00 00 00 00 02 94 09 15 01 00 00 00 00 02 95 1d 15 01 00 00 00 00 02 98 0e 15 01 00 00 00 00 02 99 20 15 01 00 00 00 00 02 9a 10 15 01 00 00 00 00 02 a0 10 15 01 00 00 00 00 02 a2 09 15 01 00 00 00 00 02 a3 06 15 01 00 00 00 00 02 aa 00 15 01 00 00 00 00 02 ab 02 15 01 00 00 00 00 02 b2 07 15 01 00 00 00 00 02 b3 02 15 01 00 00 00 00 02 ba 01 15 01 00 00 00 00 02 bb 01 15 01 00 00 00 00 02 bc 02 15 01 00 00 00 00 02 bd 00 15 01 00 00 00 00 02 c2 04 15 01 00 00 00 00 02 c3 04 15 01 00 00 00 00 02 c4 02 15 01 00 00 00 00 02 c9 05 15 01 00 00 00 00 02 ca 01 15 01 00 00 00 00 02 cb 01 15 01 00 00 00 00 02 da 70 15 01 00 00 00 00 02 db 4c 15 01 00 00 00 00 02 dc 38 15 01 00 00 00 00 02 dd 15 15 01 00 00 00 00 02 de 12 15 01 00 00 00 00 02 df 1b 15 01 00 00 00 00 02 e2 23 15 01 00 00 00 00 02 e3 3c 15 01 00 00 00 00 02 e4 28 15 01 00 00 00 00 02 ea 1f 15 01 00 00 00 00 02 eb 1a 15 01 00 00 00 00 02 ec 14 15 01 00 00 00 00 02 f3 10 15 01 00 00 00 00 02 f4 0d 15 01 00 00 00 00 02 fe 5b 15 01 00 00 00 00 02 01 12 15 01 00 00 00 00 02 02 0b 15 01 00 00 00 00 02 03 04 15 01 00 00 00 00 02 09 08 15 01 00 00 00 00 02 0a 05 15 01 00 00 00 00 02 11 08 15 01 00 00 00 00 02 12 05 15 01 00 00 00 00 02 18 0a 15 01 00 00 00 00 02 19 05 15 01 00 00 00 00 02 1b 00 15 01 00 00 00 00 02 21 03 15 01 00 00 00 00 02 22 02 15 01 00 00 00 00 02 23 02 15 01 00 00 00 00 02 24 02 15 01 00 00 00 00 02 25 04 15 01 00 00 00 00 02 29 10 15 01 00 00 00 00 02 2a ff 15 01 00 00 00 00 02 2b dc 15 01 00 00 00 00 02 2d 1f 15 01 00 00 00 00 02 2f fc 15 01 00 00 00 00 02 30 22 15 01 00 00 00 00 02 33 f8 15 01 00 00 00 00 02 34 e0 15 01 00 00 00 00 02 35 00 15 01 00 00 00 00 02 37 06 15 01 00 00 00 00 02 3b f9 15 01 00 00 00 00 02 3d ff 15 01 00 00 00 00 02 45 00 15 01 00 00 00 00 02 46 ff 15 01 00 00 00 00 02 55 00 15 01 00 00 00 00 02 56 00 15 01 00 00 00 00 02 5e fe 15 01 00 00 00 00 02 5f ff 15 01 00 00 00 00 02 60 02 15 01 00 00 00 00 02 65 fa 15 01 00 00 00 00 02 66 ff 15 01 00 00 00 00 02 67 ff 15 01 00 00 00 00 02 6e 00 15 01 00 00 00 00 02 6f 00 15 01 00 00 00 00 02 70 00 15 01 00 00 00 00 02 71 01 15 01 00 00 00 00 02 fe 9b 15 01 00 00 00 00 02 0b 4e 15 01 00 00 00 00 02 fe 00 15 01 00 00 00 00 02 c2 08 15 01 00 00 00 00 02 35 00 15 01 00 00 00 00 02 53 20 39 01 00 00 00 00 03 51 00 00 05 01 00 00 64 00 01 11 05 01 00 00 14 00 01 29];
						zte,mdss-dsi-bl-commands-state = "dsi_lp_mode";
						zte,mdss-dsi-dim-off-commands-state = "dsi_lp_mode";
						zte,mdss-dsi-dim-on-commands-state = "dsi_lp_mode";
						zte,mdss-dsi-hbm-off-aod-on-commands-state = "dsi_lp_mode";
						zte,mdss-dsi-reg-read-commands-state = "dsi_lp_mode";
						zte,mdss-dsi-aod-off-hbm-on-commands-state = "dsi_lp_mode";
						zte,mdss-dsi-restore-bl-commands-state = "dsi_lp_mode";
						zte,mdss-dsi-aod-high-commands-state = "dsi_lp_mode";
						zte,mdss-dsi-aod-mid-commands-state = "dsi_lp_mode";
						zte,mdss-dsi-aod-low-commands-state = "dsi_lp_mode";
						zte,mdss-dsi-hbm-off-commands-state = "dsi_lp_mode";
						zte,mdss-dsi-hbm-on-commands-state = "dsi_lp_mode";
						zte,mdss-dsi-bl-commands = [15 01 00 00 00 00 02 fe 00 39 01 00 00 00 00 03 51 03 ff];
						zte,mdss-dsi-dim-off-commands = [15 01 00 00 00 00 02 fe 00 15 01 00 00 00 00 02 53 20];
						zte,mdss-dsi-dim-on-commands = [15 01 00 00 00 00 02 fe 00 15 01 00 00 00 00 02 53 28];
						zte,mdss-dsi-hbm-off-aod-on-commands = [15 01 00 00 00 00 02 fe 00 39 01 00 00 00 00 03 51 00 00 05 01 00 00 00 00 01 39 39 01 00 00 00 00 03 51 01 20];
						zte,mdss-dsi-reg-read-commands = <0x6010000 0x1a0>;
						zte,mdss-dsi-aod-off-hbm-on-commands = [15 01 00 00 00 00 02 fe 00 05 01 00 00 00 00 01 38 39 01 00 00 00 00 03 51 1f fe];
						zte,mdss-dsi-acl-high-commands = [15 01 00 00 00 00 02 fe 00 15 01 00 00 00 00 02 55 11];
						zte,mdss-dsi-acl-mid-commands = [15 01 00 00 00 00 02 fe 00 15 01 00 00 00 00 02 55 12];
						zte,mdss-dsi-acl-low-commands = [15 01 00 00 00 00 02 fe 00 15 01 00 00 00 00 02 55 13];
						zte,mdss-dsi-acl-off-commands = [15 01 00 00 00 00 02 fe 00 15 01 00 00 00 00 02 55 10];
						zte,mdss-dsi-restore-bl-commands = [15 01 00 00 00 00 02 fe 00 39 01 00 00 00 00 03 51 03 ff];
						zte,mdss-dsi-aod-high-commands = [15 01 00 00 00 00 02 fe 00 39 01 00 00 00 00 03 51 1f fc];
						zte,mdss-dsi-aod-mid-commands = [15 01 00 00 00 00 02 fe 00 39 01 00 00 00 00 03 51 0a ae];
						zte,mdss-dsi-aod-low-commands = [15 01 00 00 00 00 02 fe 00 39 01 00 00 00 00 03 51 00 08];
						zte,mdss-dsi-hbm-off-commands = <0x15010000 0x2fe 0x390100 0x02 0x53203901 0x00 0x3510322>;
						zte,mdss-dsi-hbm-on-commands = <0x15010000 0x2fe 0x390100 0x02 0x53203901 0x00 0x3511ffe>;
						qcom,mdss-dsi-nolp-command-state = "dsi_lp_mode";
						qcom,mdss-dsi-nolp-command = [15 01 00 00 00 00 02 fe 00 39 01 00 00 00 00 03 51 00 00 05 01 00 00 00 00 01 38];
						qcom,mdss-dsi-lp1-command-state = "dsi_lp_mode";
						qcom,mdss-dsi-lp1-command = [15 01 00 00 00 00 02 fe 00 05 01 00 00 14 00 01 39];
						qcom,mdss-dsi-off-command-state = "dsi_lp_mode";
						qcom,mdss-dsi-off-command = [15 01 00 00 14 00 02 fe 00 05 01 00 00 10 00 01 28 05 01 00 00 78 00 01 10];
						qcom,default-topology-index = <0x00>;
						qcom,display-topology = <0x02 0x02 0x01>;
						qcom,mdss-dsc-block-prediction-enable;
						qcom,mdss-dsc-bit-per-pixel = <0x08>;
						qcom,mdss-dsc-bit-per-component = <0x0a>;
						qcom,mdss-dsc-slice-per-pkt = <0x02>;
						qcom,mdss-dsc-slice-width = <0x260>;
						qcom,mdss-dsc-slice-height = <0x10>;
						qcom,compression-mode = "dsc";
						qcom,mdss-mdp-transfer-time-us = <0x185b>;
						qcom,mdss-dsi-panel-framerate = <0x90>;
						qcom,mdss-dsi-v-bottom-border = <0x00>;
						qcom,mdss-dsi-v-top-border = <0x00>;
						qcom,mdss-dsi-h-right-border = <0x00>;
						qcom,mdss-dsi-h-left-border = <0x00>;
						qcom,mdss-dsi-h-sync-pulse = <0x00>;
						qcom,mdss-dsi-v-pulse-width = <0x08>;
						qcom,mdss-dsi-v-front-porch = <0x38>;
						qcom,mdss-dsi-v-back-porch = <0x08>;
						qcom,mdss-dsi-h-sync-skew = <0x00>;
						qcom,mdss-dsi-h-pulse-width = <0x08>;
						qcom,mdss-dsi-h-back-porch = <0x0c>;
						qcom,mdss-dsi-h-front-porch = <0x08>;
						qcom,mdss-dsi-panel-height = <0xa80>;
						qcom,mdss-dsi-panel-width = <0x4c0>;
						cell-index = <0x03>;
			};
		};
	};
};
